VERSION ""

NS_ :

BS_:

BU_: ACM AMP BCM DIAG_TEST EMCM ESEM ETM HMSM IPC LBSS RBSS TBM TTM

BO_ 1884 BCM_IGNITION_ON_COUNTER: 2 BCM
 SG_ IgnitionOnCounter : 7|16@0+ (1,0) [0|65535] "-" ACM,AMP,EMCM,ESEM,ETM,HMSM,LBSS,RBSS,TBM,TTM

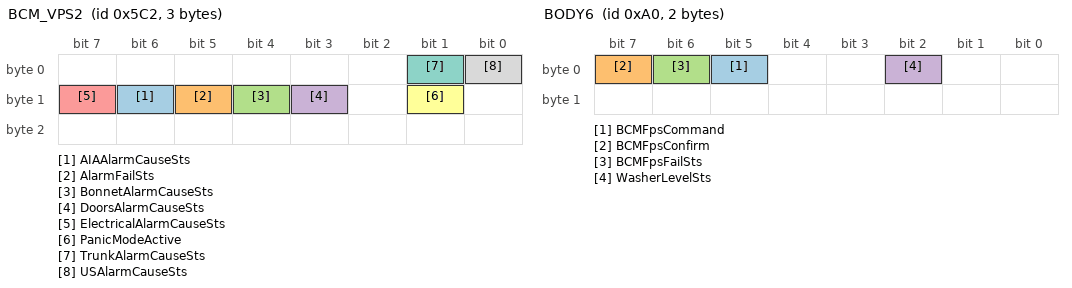
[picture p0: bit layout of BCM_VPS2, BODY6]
BO_ 1474 BCM_VPS2: 3 BCM
 SG_ AIAAlarmCauseSts : 14|1@0+ (1,0) [0|1] "-" IPC
 SG_ AlarmFailSts : 13|1@0+ (1,0) [0|1] "-" IPC
 SG_ BonnetAlarmCauseSts : 12|1@0+ (1,0) [0|1] "-" IPC
 SG_ DoorsAlarmCauseSts : 11|1@0+ (1,0) [0|1] "-" IPC
 SG_ ElectricalAlarmCauseSts : 15|1@0+ (1,0) [0|1] "-" IPC
 SG_ PanicModeActive : 9|1@0+ (1,0) [0|1] "-" ETM
 SG_ TrunkAlarmCauseSts : 1|1@0+ (1,0) [0|1] "-" IPC
 SG_ USAlarmCauseSts : 0|1@0+ (1,0) [0|1] "-" IPC

BO_ 160 BODY6: 2 BCM
 SG_ BCMFpsCommand : 5|1@0+ (1,0) [0|1] "-" ACM
 SG_ BCMFpsConfirm : 7|1@0+ (1,0) [0|1] "-" ACM
 SG_ BCMFpsFailSts : 6|1@0+ (1,0) [0|1] "-" ACM
 SG_ WasherLevelSts : 2|1@0+ (1,0) [0|1] "-" IPC

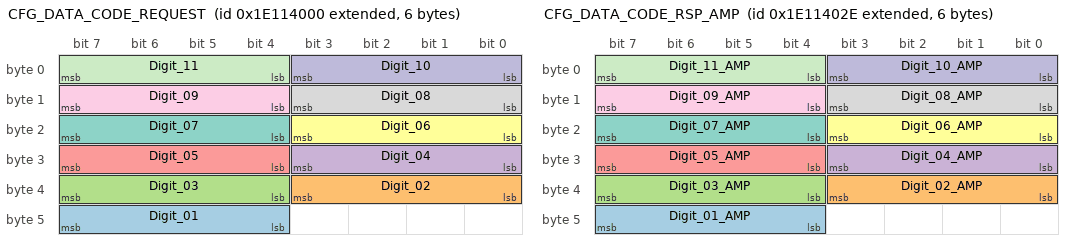
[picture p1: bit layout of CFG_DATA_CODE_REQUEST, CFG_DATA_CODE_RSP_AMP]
BO_ 2651930624 CFG_DATA_CODE_REQUEST: 6 BCM
 SG_ Digit_01 : 47|4@0+ (1,0) [0|15] "" ACM,AMP,EMCM,ESEM,ETM,HMSM,LBSS,RBSS,TBM,TTM
 SG_ Digit_02 : 35|4@0+ (1,0) [0|15] "" ACM,AMP,EMCM,ESEM,ETM,HMSM,LBSS,RBSS,TBM,TTM
 SG_ Digit_03 : 39|4@0+ (1,0) [0|15] "" ACM,AMP,EMCM,ESEM,ETM,HMSM,LBSS,RBSS,TBM,TTM
 SG_ Digit_04 : 27|4@0+ (1,0) [0|15] "" ACM,AMP,EMCM,ESEM,ETM,HMSM,LBSS,RBSS,TBM,TTM
 SG_ Digit_05 : 31|4@0+ (1,0) [0|15] "" ACM,AMP,EMCM,ESEM,ETM,HMSM,LBSS,RBSS,TBM,TTM
 SG_ Digit_06 : 19|4@0+ (1,0) [0|15] "" ACM,AMP,EMCM,ESEM,ETM,HMSM,LBSS,RBSS,TBM,TTM
 SG_ Digit_07 : 23|4@0+ (1,0) [0|15] "" ACM,AMP,EMCM,ESEM,ETM,HMSM,LBSS,RBSS,TBM,TTM
 SG_ Digit_08 : 11|4@0+ (1,0) [0|15] "" ACM,AMP,EMCM,ESEM,ETM,HMSM,LBSS,RBSS,TBM,TTM
 SG_ Digit_09 : 15|4@0+ (1,0) [0|15] "" ACM,AMP,EMCM,ESEM,ETM,HMSM,LBSS,RBSS,TBM,TTM
 SG_ Digit_10 : 3|4@0+ (1,0) [0|15] "" ACM,AMP,EMCM,ESEM,ETM,HMSM,LBSS,RBSS,TBM,TTM
 SG_ Digit_11 : 7|4@0+ (1,0) [0|15] "" ACM,AMP,EMCM,ESEM,ETM,HMSM,LBSS,RBSS,TBM,TTM

BO_ 2651930670 CFG_DATA_CODE_RSP_AMP: 6 AMP
 SG_ Digit_01_AMP : 47|4@0+ (1,0) [0|15] "-" BCM
 SG_ Digit_02_AMP : 35|4@0+ (1,0) [0|15] "-" BCM
 SG_ Digit_03_AMP : 39|4@0+ (1,0) [0|15] "-" BCM
 SG_ Digit_04_AMP : 27|4@0+ (1,0) [0|15] "-" BCM
 SG_ Digit_05_AMP : 31|4@0+ (1,0) [0|15] "-" BCM
 SG_ Digit_06_AMP : 19|4@0+ (1,0) [0|15] "-" BCM
 SG_ Digit_07_AMP : 23|4@0+ (1,0) [0|15] "-" BCM
 SG_ Digit_08_AMP : 11|4@0+ (1,0) [0|15] "-" BCM
 SG_ Digit_09_AMP : 15|4@0+ (1,0) [0|15] "-" BCM
 SG_ Digit_10_AMP : 3|4@0+ (1,0) [0|15] "-" BCM
 SG_ Digit_11_AMP : 7|4@0+ (1,0) [0|15] "-" BCM

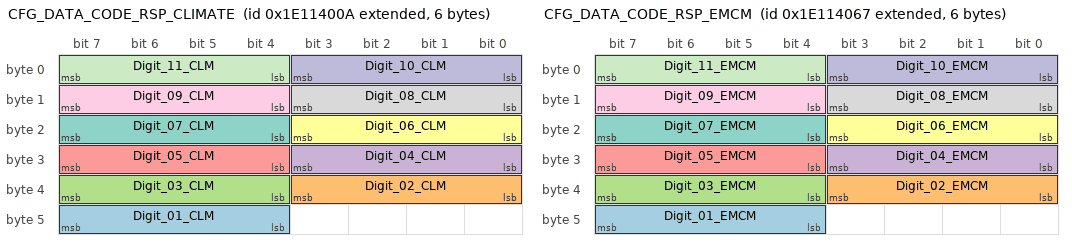
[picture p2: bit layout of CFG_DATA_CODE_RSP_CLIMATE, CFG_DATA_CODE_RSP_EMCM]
BO_ 2651930634 CFG_DATA_CODE_RSP_CLIMATE: 6 ACM
 SG_ Digit_01_CLM : 47|4@0+ (1,0) [0|15] "-" BCM
 SG_ Digit_02_CLM : 35|4@0+ (1,0) [0|15] "-" BCM
 SG_ Digit_03_CLM : 39|4@0+ (1,0) [0|15] "-" BCM
 SG_ Digit_04_CLM : 27|4@0+ (1,0) [0|15] "-" BCM
 SG_ Digit_05_CLM : 31|4@0+ (1,0) [0|15] "-" BCM
 SG_ Digit_06_CLM : 19|4@0+ (1,0) [0|15] "-" BCM
 SG_ Digit_07_CLM : 23|4@0+ (1,0) [0|15] "-" BCM
 SG_ Digit_08_CLM : 11|4@0+ (1,0) [0|15] "-" BCM
 SG_ Digit_09_CLM : 15|4@0+ (1,0) [0|15] "-" BCM
 SG_ Digit_10_CLM : 3|4@0+ (1,0) [0|15] "-" BCM
 SG_ Digit_11_CLM : 7|4@0+ (1,0) [0|15] "-" BCM

BO_ 2651930727 CFG_DATA_CODE_RSP_EMCM: 6 EMCM
 SG_ Digit_01_EMCM : 47|4@0+ (1,0) [0|15] "-" BCM
 SG_ Digit_02_EMCM : 35|4@0+ (1,0) [0|15] "-" BCM
 SG_ Digit_03_EMCM : 39|4@0+ (1,0) [0|15] "-" BCM
 SG_ Digit_04_EMCM : 27|4@0+ (1,0) [0|15] "-" BCM
 SG_ Digit_05_EMCM : 31|4@0+ (1,0) [0|15] "-" BCM
 SG_ Digit_06_EMCM : 19|4@0+ (1,0) [0|15] "-" BCM
 SG_ Digit_07_EMCM : 23|4@0+ (1,0) [0|15] "-" BCM
 SG_ Digit_08_EMCM : 11|4@0+ (1,0) [0|15] "-" BCM
 SG_ Digit_09_EMCM : 15|4@0+ (1,0) [0|15] "-" BCM
 SG_ Digit_10_EMCM : 3|4@0+ (1,0) [0|15] "-" BCM
 SG_ Digit_11_EMCM : 7|4@0+ (1,0) [0|15] "-" BCM

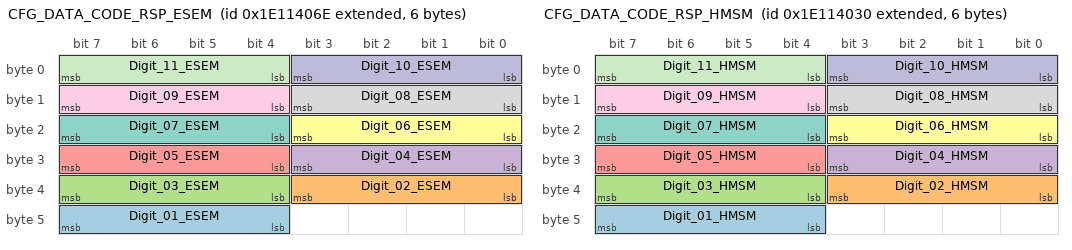
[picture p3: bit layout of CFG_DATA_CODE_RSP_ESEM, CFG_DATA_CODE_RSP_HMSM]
BO_ 2651930734 CFG_DATA_CODE_RSP_ESEM: 6 ESEM
 SG_ Digit_01_ESEM : 47|4@0+ (1,0) [0|15] "-" BCM
 SG_ Digit_02_ESEM : 35|4@0+ (1,0) [0|15] "-" BCM
 SG_ Digit_03_ESEM : 39|4@0+ (1,0) [0|15] "-" BCM
 SG_ Digit_04_ESEM : 27|4@0+ (1,0) [0|15] "-" BCM
 SG_ Digit_05_ESEM : 31|4@0+ (1,0) [0|15] "-" BCM
 SG_ Digit_06_ESEM : 19|4@0+ (1,0) [0|15] "-" BCM
 SG_ Digit_07_ESEM : 23|4@0+ (1,0) [0|15] "-" BCM
 SG_ Digit_08_ESEM : 11|4@0+ (1,0) [0|15] "-" BCM
 SG_ Digit_09_ESEM : 15|4@0+ (1,0) [0|15] "-" BCM
 SG_ Digit_10_ESEM : 3|4@0+ (1,0) [0|15] "-" BCM
 SG_ Digit_11_ESEM : 7|4@0+ (1,0) [0|15] "-" BCM

BO_ 2651930672 CFG_DATA_CODE_RSP_HMSM: 6 HMSM
 SG_ Digit_01_HMSM : 47|4@0+ (1,0) [0|15] "-" BCM
 SG_ Digit_02_HMSM : 35|4@0+ (1,0) [0|15] "-" BCM
 SG_ Digit_03_HMSM : 39|4@0+ (1,0) [0|15] "-" BCM
 SG_ Digit_04_HMSM : 27|4@0+ (1,0) [0|15] "-" BCM
 SG_ Digit_05_HMSM : 31|4@0+ (1,0) [0|15] "-" BCM
 SG_ Digit_06_HMSM : 19|4@0+ (1,0) [0|15] "-" BCM
 SG_ Digit_07_HMSM : 23|4@0+ (1,0) [0|15] "-" BCM
 SG_ Digit_08_HMSM : 11|4@0+ (1,0) [0|15] "-" BCM
 SG_ Digit_09_HMSM : 15|4@0+ (1,0) [0|15] "-" BCM
 SG_ Digit_10_HMSM : 3|4@0+ (1,0) [0|15] "-" BCM
 SG_ Digit_11_HMSM : 7|4@0+ (1,0) [0|15] "-" BCM

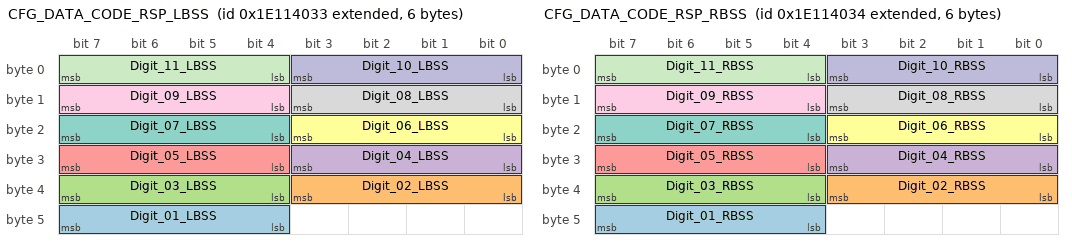
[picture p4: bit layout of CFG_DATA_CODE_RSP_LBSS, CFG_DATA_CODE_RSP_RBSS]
BO_ 2651930675 CFG_DATA_CODE_RSP_LBSS: 6 LBSS
 SG_ Digit_01_LBSS : 47|4@0+ (1,0) [0|15] "-" BCM
 SG_ Digit_02_LBSS : 35|4@0+ (1,0) [0|15] "-" BCM
 SG_ Digit_03_LBSS : 39|4@0+ (1,0) [0|15] "-" BCM
 SG_ Digit_04_LBSS : 27|4@0+ (1,0) [0|15] "-" BCM
 SG_ Digit_05_LBSS : 31|4@0+ (1,0) [0|15] "-" BCM
 SG_ Digit_06_LBSS : 19|4@0+ (1,0) [0|15] "-" BCM
 SG_ Digit_07_LBSS : 23|4@0+ (1,0) [0|15] "-" BCM
 SG_ Digit_08_LBSS : 11|4@0+ (1,0) [0|15] "-" BCM
 SG_ Digit_09_LBSS : 15|4@0+ (1,0) [0|15] "-" BCM
 SG_ Digit_10_LBSS : 3|4@0+ (1,0) [0|15] "-" BCM
 SG_ Digit_11_LBSS : 7|4@0+ (1,0) [0|15] "-" BCM

BO_ 2651930676 CFG_DATA_CODE_RSP_RBSS: 6 RBSS
 SG_ Digit_01_RBSS : 47|4@0+ (1,0) [0|15] "-" BCM
 SG_ Digit_02_RBSS : 35|4@0+ (1,0) [0|15] "-" BCM
 SG_ Digit_03_RBSS : 39|4@0+ (1,0) [0|15] "-" BCM
 SG_ Digit_04_RBSS : 27|4@0+ (1,0) [0|15] "-" BCM
 SG_ Digit_05_RBSS : 31|4@0+ (1,0) [0|15] "-" BCM
 SG_ Digit_06_RBSS : 19|4@0+ (1,0) [0|15] "-" BCM
 SG_ Digit_07_RBSS : 23|4@0+ (1,0) [0|15] "-" BCM
 SG_ Digit_08_RBSS : 11|4@0+ (1,0) [0|15] "-" BCM
 SG_ Digit_09_RBSS : 15|4@0+ (1,0) [0|15] "-" BCM
 SG_ Digit_10_RBSS : 3|4@0+ (1,0) [0|15] "-" BCM
 SG_ Digit_11_RBSS : 7|4@0+ (1,0) [0|15] "-" BCM

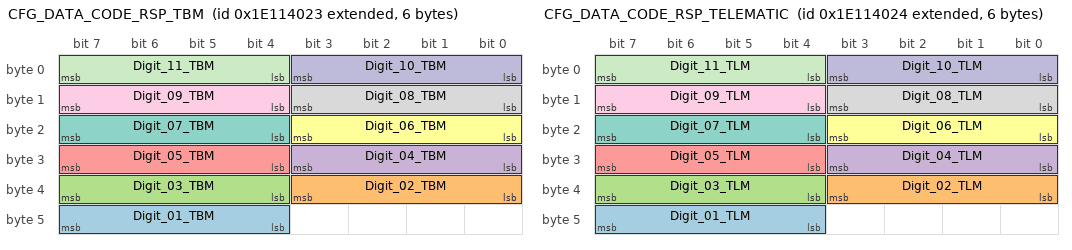
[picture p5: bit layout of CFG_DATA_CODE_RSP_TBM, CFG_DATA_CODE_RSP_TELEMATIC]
BO_ 2651930659 CFG_DATA_CODE_RSP_TBM: 6 TBM
 SG_ Digit_01_TBM : 47|4@0+ (1,0) [0|15] "-" BCM
 SG_ Digit_02_TBM : 35|4@0+ (1,0) [0|15] "-" BCM
 SG_ Digit_03_TBM : 39|4@0+ (1,0) [0|15] "-" BCM
 SG_ Digit_04_TBM : 27|4@0+ (1,0) [0|15] "-" BCM
 SG_ Digit_05_TBM : 31|4@0+ (1,0) [0|15] "-" BCM
 SG_ Digit_06_TBM : 19|4@0+ (1,0) [0|15] "-" BCM
 SG_ Digit_07_TBM : 23|4@0+ (1,0) [0|15] "-" BCM
 SG_ Digit_08_TBM : 11|4@0+ (1,0) [0|15] "-" BCM
 SG_ Digit_09_TBM : 15|4@0+ (1,0) [0|15] "-" BCM
 SG_ Digit_10_TBM : 3|4@0+ (1,0) [0|15] "-" BCM
 SG_ Digit_11_TBM : 7|4@0+ (1,0) [0|15] "-" BCM

BO_ 2651930660 CFG_DATA_CODE_RSP_TELEMATIC: 6 ETM
 SG_ Digit_01_TLM : 47|4@0+ (1,0) [0|15] "-" BCM
 SG_ Digit_02_TLM : 35|4@0+ (1,0) [0|15] "-" BCM
 SG_ Digit_03_TLM : 39|4@0+ (1,0) [0|15] "-" BCM
 SG_ Digit_04_TLM : 27|4@0+ (1,0) [0|15] "-" BCM
 SG_ Digit_05_TLM : 31|4@0+ (1,0) [0|15] "-" BCM
 SG_ Digit_06_TLM : 19|4@0+ (1,0) [0|15] "-" BCM
 SG_ Digit_07_TLM : 23|4@0+ (1,0) [0|15] "-" BCM
 SG_ Digit_08_TLM : 11|4@0+ (1,0) [0|15] "-" BCM
 SG_ Digit_09_TLM : 15|4@0+ (1,0) [0|15] "-" BCM
 SG_ Digit_10_TLM : 3|4@0+ (1,0) [0|15] "-" BCM
 SG_ Digit_11_TLM : 7|4@0+ (1,0) [0|15] "-" BCM

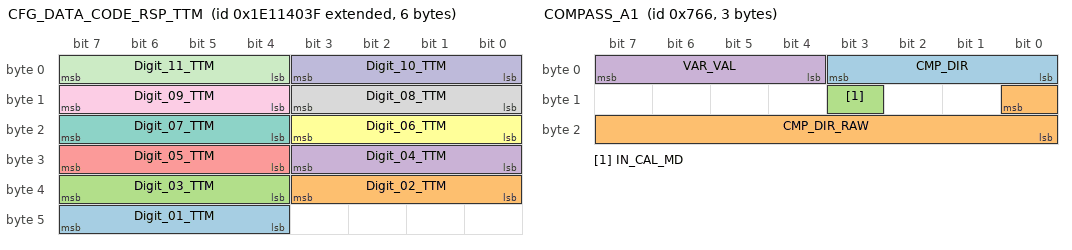
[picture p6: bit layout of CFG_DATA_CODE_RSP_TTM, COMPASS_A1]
BO_ 2651930687 CFG_DATA_CODE_RSP_TTM: 6 TTM
 SG_ Digit_01_TTM : 47|4@0+ (1,0) [0|15] "-" BCM
 SG_ Digit_02_TTM : 35|4@0+ (1,0) [0|15] "-" BCM
 SG_ Digit_03_TTM : 39|4@0+ (1,0) [0|15] "-" BCM
 SG_ Digit_04_TTM : 27|4@0+ (1,0) [0|15] "-" BCM
 SG_ Digit_05_TTM : 31|4@0+ (1,0) [0|15] "-" BCM
 SG_ Digit_06_TTM : 19|4@0+ (1,0) [0|15] "-" BCM
 SG_ Digit_07_TTM : 23|4@0+ (1,0) [0|15] "-" BCM
 SG_ Digit_08_TTM : 11|4@0+ (1,0) [0|15] "-" BCM
 SG_ Digit_09_TTM : 15|4@0+ (1,0) [0|15] "-" BCM
 SG_ Digit_10_TTM : 3|4@0+ (1,0) [0|15] "-" BCM
 SG_ Digit_11_TTM : 7|4@0+ (1,0) [0|15] "-" BCM

BO_ 134 CLIMATE_REQ: 2 ACM
 SG_ FPS_Status_Request : 7|1@0+ (1,0) [0|1] "-" BCM

BO_ 1894 COMPASS_A1: 3 IPC
 SG_ CMP_DIR : 3|4@0+ (1,0) [0|15] "" ETM
 SG_ CMP_DIR_RAW : 8|9@0+ (1,0) [0|0] "" Vector__XXX
 SG_ IN_CAL_MD : 11|1@0+ (1,0) [0|0] "" ETM
 SG_ VAR_VAL : 7|4@0+ (1,0) [0|0] "" ETM

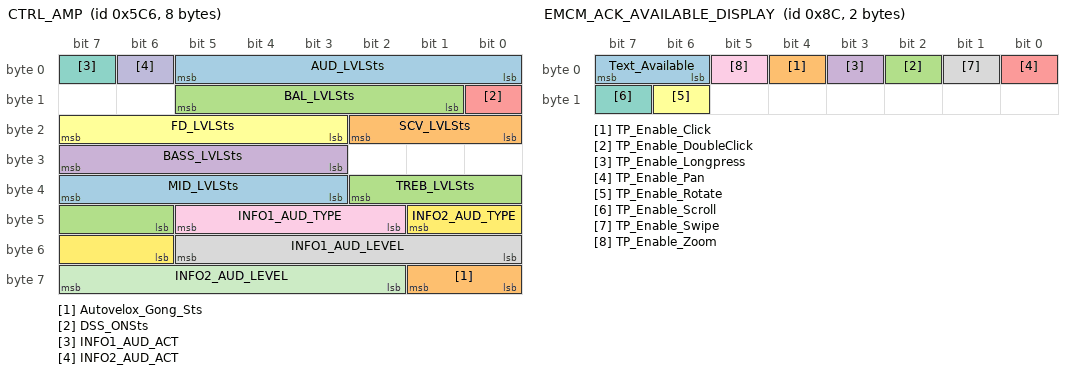
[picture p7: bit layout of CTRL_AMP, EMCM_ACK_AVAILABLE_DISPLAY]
BO_ 1478 CTRL_AMP: 8 ETM
 SG_ AUD_LVLSts : 5|6@0+ (1,0) [0|63] "" AMP
 SG_ Autovelox_Gong_Sts : 57|2@0+ (1,0) [0|3] "" AMP
 SG_ BAL_LVLSts : 13|5@0+ (1,0) [0|31] "" AMP
 SG_ BASS_LVLSts : 31|5@0+ (1,0) [0|31] "" AMP
 SG_ DSS_ONSts : 8|1@0+ (1,0) [0|1] "" AMP
 SG_ FD_LVLSts : 23|5@0+ (1,0) [0|31] "" AMP
 SG_ INFO1_AUD_ACT : 7|1@0+ (1,0) [0|1] "" AMP
 SG_ INFO1_AUD_LEVEL : 53|6@0+ (1,0) [0|63] "" AMP
 SG_ INFO1_AUD_TYPE : 45|4@0+ (1,0) [0|15] "" AMP
 SG_ INFO2_AUD_ACT : 6|1@0+ (1,0) [0|1] "" AMP
 SG_ INFO2_AUD_LEVEL : 63|6@0+ (1,0) [0|63] "" AMP
 SG_ INFO2_AUD_TYPE : 41|4@0+ (1,0) [0|15] "" AMP
 SG_ MID_LVLSts : 39|5@0+ (1,0) [0|31] "" AMP
 SG_ SCV_LVLSts : 18|3@0+ (1,0) [0|6] "" AMP
 SG_ TREB_LVLSts : 34|5@0+ (1,0) [0|31] "" AMP

BO_ 2564554481 DIAGNOSTIC_REQ_FUNC_BH_C2: 8 BCM
 SG_ N_PDU : 7|64@0+ (1,0) [0|0] "" ACM,AMP,BCM,EMCM,ESEM,ETM,HMSM,LBSS,RBSS,TBM,TTM

BO_ 2564457457 DIAGNOSTIC_REQUEST_AMP: 8 BCM
 SG_ N_PDU : 7|64@0+ (1,0) [0|0] "" AMP

BO_ 2564462833 DIAGNOSTIC_REQUEST_CLIMATE: 8 BCM
 SG_ N_PDU : 7|64@0+ (1,0) [0|0] "" ACM

BO_ 2564459249 DIAGNOSTIC_REQUEST_EMCM: 8 BCM
 SG_ N_PDU : 7|64@0+ (1,0) [0|0] "" EMCM

BO_ 2564459505 DIAGNOSTIC_REQUEST_ESEM: 8 BCM
 SG_ N_PDU : 7|64@0+ (1,0) [0|0] "" ESEM

BO_ 2564473585 DIAGNOSTIC_REQUEST_HMSM: 8 BCM
 SG_ N_PDU : 7|64@0+ (1,0) [0|0] "" HMSM

BO_ 2564449009 DIAGNOSTIC_REQUEST_LBSS: 8 BCM
 SG_ N_PDU : 7|64@0+ (1,0) [0|0] "" LBSS

BO_ 2564449777 DIAGNOSTIC_REQUEST_RBSS: 8 BCM
 SG_ N_PDU : 7|64@0+ (1,0) [0|0] "" RBSS

BO_ 2564474609 DIAGNOSTIC_REQUEST_TBM: 8 BCM
 SG_ N_PDU : 7|64@0+ (1,0) [0|0] "-" TBM

BO_ 2564458481 DIAGNOSTIC_REQUEST_TELEMATIC: 8 BCM
 SG_ N_PDU : 7|64@0+ (1,0) [0|0] "" EMCM,ESEM,ETM

BO_ 2564442865 DIAGNOSTIC_REQUEST_TTM: 8 BCM
 SG_ N_PDU : 7|64@0+ (1,0) [0|0] "" TTM

BO_ 2564485507 DIAGNOSTIC_RESPONSE_AMP: 8 AMP
 SG_ N_PDU : 7|64@0+ (1,0) [0|0] "-" BCM,DIAG_TEST

BO_ 2564485528 DIAGNOSTIC_RESPONSE_CLIMATE: 8 ACM
 SG_ N_PDU : 7|64@0+ (1,0) [0|0] "" BCM,DIAG_TEST

BO_ 2564485514 DIAGNOSTIC_RESPONSE_EMCM: 8 EMCM
 SG_ N_PDU : 7|64@0+ (1,0) [0|0] "-" DIAG_TEST

BO_ 2564485515 DIAGNOSTIC_RESPONSE_ESEM: 8 ESEM
 SG_ N_PDU : 7|64@0+ (1,0) [0|0] "" BCM,DIAG_TEST

BO_ 2564485570 DIAGNOSTIC_RESPONSE_HMSM: 8 HMSM
 SG_ N_PDU : 7|64@0+ (1,0) [0|0] "-" BCM,DIAG_TEST

BO_ 2564485474 DIAGNOSTIC_RESPONSE_LBSS: 8 LBSS
 SG_ N_PDU : 7|64@0+ (1,0) [0|0] "-" BCM,DIAG_TEST

BO_ 2564485477 DIAGNOSTIC_RESPONSE_RBSS: 8 RBSS
 SG_ N_PDU : 7|64@0+ (1,0) [0|0] "-" BCM,DIAG_TEST

BO_ 2564485574 DIAGNOSTIC_RESPONSE_TBM: 8 TBM
 SG_ N_PDU : 7|64@0+ (1,0) [0|0] "-" BCM,DIAG_TEST

BO_ 2564485511 DIAGNOSTIC_RESPONSE_TELEMATIC: 8 ETM
 SG_ N_PDU : 7|64@0+ (1,0) [0|0] "" BCM,DIAG_TEST

BO_ 2564485450 DIAGNOSTIC_RESPONSE_TTM: 8 TTM
 SG_ N_PDU : 7|64@0+ (1,0) [0|0] "-" BCM,DIAG_TEST

BO_ 140 EMCM_ACK_AVAILABLE_DISPLAY: 2 EMCM
 SG_ Text_Available : 7|2@0+ (1,0) [0|3] "-" ETM
 SG_ TP_Enable_Click : 4|1@0+ (1,0) [0|1] "-" ETM
 SG_ TP_Enable_DoubleClick : 2|1@0+ (1,0) [0|1] "-" ETM
 SG_ TP_Enable_Longpress : 3|1@0+ (1,0) [0|1] "-" ETM
 SG_ TP_Enable_Pan : 0|1@0+ (1,0) [0|1] "-" ETM
 SG_ TP_Enable_Rotate : 14|1@0+ (1,0) [0|1] "-" ETM
 SG_ TP_Enable_Scroll : 15|1@0+ (1,0) [0|1] "-" ETM
 SG_ TP_Enable_Swipe : 1|1@0+ (1,0) [0|1] "-" ETM
 SG_ TP_Enable_Zoom : 5|1@0+ (1,0) [0|1] "-" ETM

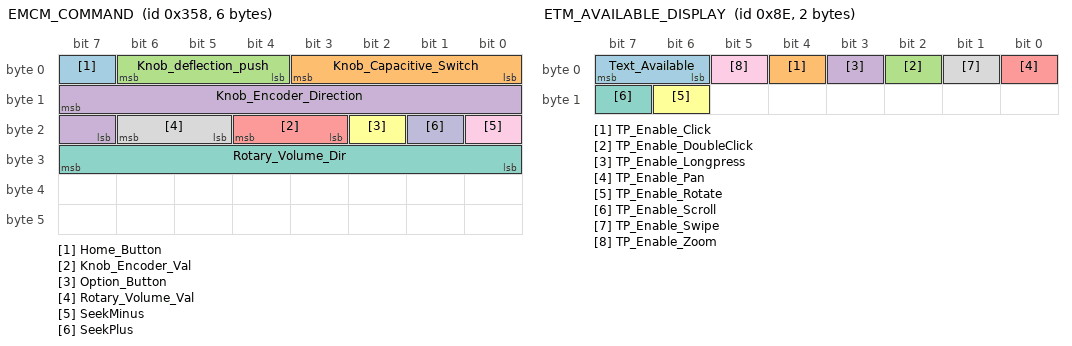
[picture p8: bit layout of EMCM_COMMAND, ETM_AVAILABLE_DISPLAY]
BO_ 856 EMCM_COMMAND: 6 EMCM
 SG_ Home_Button : 7|1@0+ (1,0) [0|1] "-" ETM
 SG_ Knob_Capacitive_Switch : 3|4@0+ (1,0) [0|15] "-" ETM
 SG_ Knob_deflection_push : 6|3@0+ (1,0) [0|3] "-" ETM
 SG_ Knob_Encoder_Direction : 15|9@0+ (1,0) [0|511] "-" ETM
 SG_ Knob_Encoder_Val : 20|2@0+ (1,0) [0|3] "-" ETM
 SG_ Option_Button : 18|1@0+ (1,0) [0|1] "-" ETM
 SG_ Rotary_Volume_Dir : 31|8@0+ (1,0) [0|255] "-" ETM
 SG_ Rotary_Volume_Val : 22|2@0+ (1,0) [0|3] "-" ETM
 SG_ SeekMinus : 16|1@0+ (1,0) [0|1] "-" ETM
 SG_ SeekPlus : 17|1@0+ (1,0) [0|1] "-" ETM

BO_ 142 ETM_AVAILABLE_DISPLAY: 2 ETM
 SG_ Text_Available : 7|2@0+ (1,0) [0|3] "-" EMCM
 SG_ TP_Enable_Click : 4|1@0+ (1,0) [0|1] "-" EMCM
 SG_ TP_Enable_DoubleClick : 2|1@0+ (1,0) [0|1] "-" EMCM
 SG_ TP_Enable_Longpress : 3|1@0+ (1,0) [0|1] "-" EMCM
 SG_ TP_Enable_Pan : 0|1@0+ (1,0) [0|1] "-" EMCM
 SG_ TP_Enable_Rotate : 14|1@0+ (1,0) [0|1] "-" EMCM
 SG_ TP_Enable_Scroll : 15|1@0+ (1,0) [0|1] "-" EMCM
 SG_ TP_Enable_Swipe : 1|1@0+ (1,0) [0|1] "-" EMCM
 SG_ TP_Enable_Zoom : 5|1@0+ (1,0) [0|1] "-" EMCM

BO_ 852 EXTERNAL_LIGHTS: 4 BCM
 SG_ AHBFeature : 19|1@0+ (1,0) [0|1] "-" IPC
 SG_ ALBFeature : 30|1@0+ (1,0) [0|1] "-" IPC
 SG_ DRLFault : 6|1@0+ (1,0) [0|1] "-" IPC
 SG_ FHeatedWindowSts : 5|1@0+ (1,0) [0|1] "-" ACM
 SG_ FrontFogLightSts : 4|1@0+ (1,0) [0|1] "-" IPC
 SG_ HeatedMirrorSts : 3|1@0+ (1,0) [0|1] "-" Vector__XXX
 SG_ HighBeamSts : 2|1@0+ (1,0) [0|1] "-" IPC
 SG_ L_TurnLightActivationSts : 17|1@0+ (1,0) [0|1] "-" Vector__XXX
 SG_ LHParkingLightSts : 1|1@0+ (1,0) [0|1] "-" IPC,TTM
 SG_ LHTurnLightFault : 0|1@0+ (1,0) [0|1] "-" IPC
 SG_ LHTurnSignalSts : 15|1@0+ (1,0) [0|1] "-" IPC,TTM
 SG_ LowBeamSts : 14|1@0+ (1,0) [0|1] "-" BCM,IPC
 SG_ ParkingLightFault : 13|1@0+ (1,0) [0|1] "-" IPC
 SG_ PlateLightFault : 12|1@0+ (1,0) [0|1] "-" IPC
 SG_ R_TurnLightActivationSts : 16|1@0+ (1,0) [0|1] "-" Vector__XXX
 SG_ RearFogLightFault : 11|1@0+ (1,0) [0|1] "-" IPC
 SG_ RearFogLightSts : 10|1@0+ (1,0) [0|1] "-" IPC,TTM
 SG_ ReverseGearLightFault : 9|1@0+ (1,0) [0|1] "-" IPC
 SG_ RHeatedWindowSts : 8|1@0+ (1,0) [0|1] "-" ACM
 SG_ RHParkingLightSts : 23|1@0+ (1,0) [0|1] "-" IPC,TTM
 SG_ RHTurnLightFault : 22|1@0+ (1,0) [0|1] "-" IPC
 SG_ RHTurnSignalSts : 21|1@0+ (1,0) [0|1] "-" IPC,TTM
 SG_ StopLightFault : 20|1@0+ (1,0) [0|1] "-" IPC
 SG_ StopLightSts : 18|1@0+ (1,0) [0|1] "-" TTM

BO_ 2147485498 GPS_POS1: 8 TBM
 SG_ GPS_POS1_Lat : 39|32@0+ (0.3017485143,-324000000) [-324000000|324000000] "mass" Vector__XXX
 SG_ GPS_POS1_Long : 7|32@0+ (0.3017485143,-324000000) [-324000000|324000000] "mass" Vector__XXX

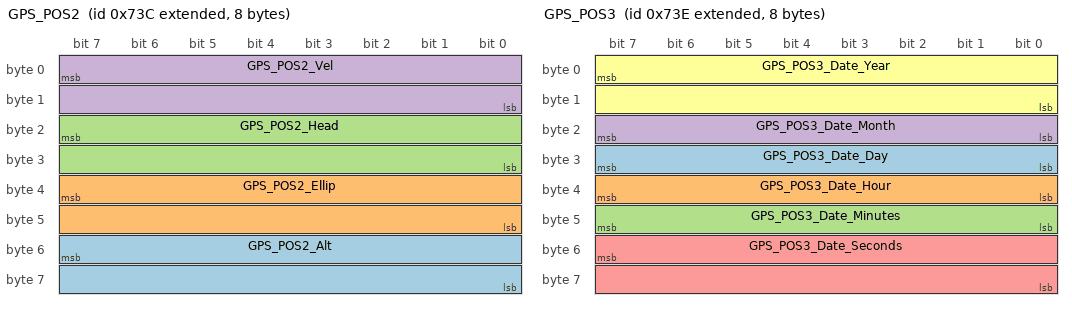
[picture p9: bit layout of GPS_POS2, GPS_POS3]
BO_ 2147485500 GPS_POS2: 8 TBM
 SG_ GPS_POS2_Alt : 55|16@0+ (0.289926,-1000) [-1000|18000] "m" Vector__XXX
 SG_ GPS_POS2_Ellip : 39|16@0+ (0.289926,-1000) [-1000|18000] "m" Vector__XXX
 SG_ GPS_POS2_Head : 23|16@0+ (0.1,0) [0|359.9] "°" Vector__XXX
 SG_ GPS_POS2_Vel : 7|16@0+ (1,0) [0|65534] "cm/sec" Vector__XXX

BO_ 2147485502 GPS_POS3: 8 TBM
 SG_ GPS_POS3_Date_Day : 31|8@0+ (31,1) [1|31] "days" Vector__XXX
 SG_ GPS_POS3_Date_Hour : 39|8@0+ (1,0) [0|23] "hours" Vector__XXX
 SG_ GPS_POS3_Date_Minutes : 47|8@0+ (59,0) [0|59] "minutes" Vector__XXX
 SG_ GPS_POS3_Date_Month : 23|8@0+ (1,0) [1|12] "months" Vector__XXX
 SG_ GPS_POS3_Date_Seconds : 55|16@0+ (0.01,0) [0|59.99] "seconds" Vector__XXX
 SG_ GPS_POS3_Date_Year : 7|16@0+ (1,0) [0|65534] "years" Vector__XXX

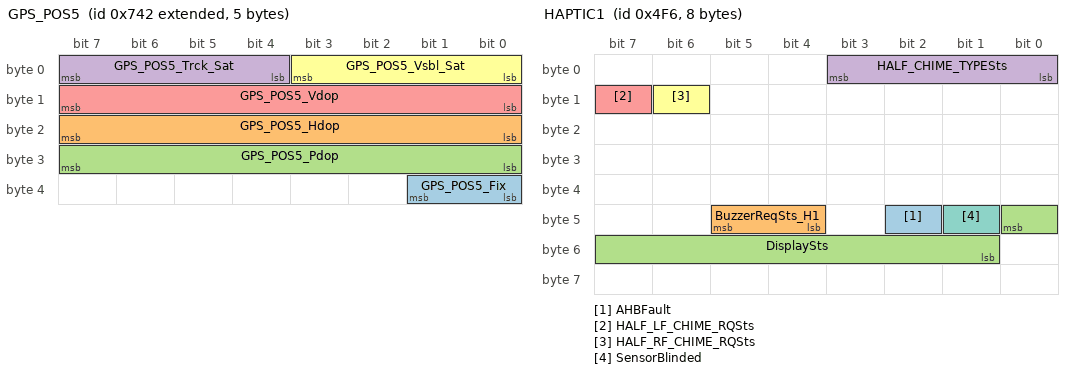
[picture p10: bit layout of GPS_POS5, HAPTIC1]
BO_ 2147485506 GPS_POS5: 5 TBM
 SG_ GPS_POS5_Fix : 33|2@0+ (1,0) [0|0] "-" Vector__XXX
 SG_ GPS_POS5_Hdop : 23|8@0+ (0.1,0) [1|8] "" Vector__XXX
 SG_ GPS_POS5_Pdop : 31|8@0+ (0.1,0) [1|8] "" Vector__XXX
 SG_ GPS_POS5_Trck_Sat : 7|4@0+ (1,0) [0|12] "" Vector__XXX
 SG_ GPS_POS5_Vdop : 15|8@0+ (0.1,0) [1|8] "" Vector__XXX
 SG_ GPS_POS5_Vsbl_Sat : 3|4@0+ (1,0) [0|12] "" Vector__XXX

BO_ 1270 HAPTIC1: 8 BCM
 SG_ AHBFault : 42|1@0+ (1,0) [0|1] "" IPC
 SG_ BuzzerReqSts_H1 : 45|2@0+ (1,0) [0|3] "" IPC
 SG_ DisplaySts : 40|8@0+ (1,0) [0|255] "-" IPC
 SG_ HALF_CHIME_TYPESts : 3|4@0+ (1,0) [0|15] "-" AMP,ETM
 SG_ HALF_LF_CHIME_RQSts : 15|1@0+ (1,0) [0|1] "-" AMP,ETM
 SG_ HALF_RF_CHIME_RQSts : 14|1@0+ (1,0) [0|1] "-" AMP,ETM
 SG_ SensorBlinded : 41|1@0+ (1,0) [0|1] "" IPC

BO_ 986 IPC_ACK: 1 IPC
 SG_ DisplayInfoReceptionSts : 7|1@0+ (1,0) [0|1] "-" ETM

BO_ 1468 IPC_VEHICLE_SETUP: 8 IPC
 SG_ AmbientLightingLevel : 48|4@0+ (1,0) [0|15] "" BCM,ETM
 SG_ AudioRepetition : 46|1@0+ (1,0) [0|1] "" ETM
 SG_ AutoHighBeamEnable : 21|1@0+ (1,0) [0|1] "-" BCM,ETM
 SG_ AutomaticResetTripB : 37|2@0+ (1,0) [0|3] "" ETM
 SG_ AutoParkBrake : 47|1@0+ (1,0) [0|1] "" ETM
 SG_ AutoRelock : 51|1@0+ (1,0) [0|1] "" ETM
 SG_ BSDEnable : 30|2@0+ (1,0) [0|3] "" ETM,LBSS,RBSS
 SG_ ConsumptionUnit : 15|3@0+ (1,0) [0|7] "-" ETM
 SG_ CorneringEnable : 18|1@0+ (1,0) [0|1] "-" BCM,ETM
 SG_ DistanceUnit : 10|1@0+ (1,0) [0|1] "-" ETM
 SG_ DRLEnable : 12|1@0+ (1,0) [0|1] "-" BCM,ETM
 SG_ ExternalLightSensorLevel : 9|2@0+ (1,0) [0|3] "-" BCM,ETM
 SG_ GreetingLightsEnable : 11|1@0+ (1,0) [0|1] "-" BCM,ETM
 SG_ HourMode : 23|1@0+ (1,0) [0|1] "-" ETM
 SG_ LanguageSelection : 7|8@0+ (1,0) [0|255] "-" ETM,TBM
 SG_ NavRepetition : 50|1@0+ (1,0) [0|1] "" ETM
 SG_ PamAlertMode : 43|2@0+ (1,0) [0|3] "-" AMP,ETM
 SG_ PamChimeVolumeFront : 45|2@0+ (1,0) [0|3] "" AMP,ETM
 SG_ PamChimeVolumeRear : 41|2@0+ (1,0) [0|3] "" AMP,ETM
 SG_ PassiveEntry : 28|1@0+ (1,0) [0|1] "" BCM,ETM
 SG_ PhoneRepetition : 49|1@0+ (1,0) [0|1] "" ETM
 SG_ RemoteDoorUnlock : 32|1@0+ (1,0) [0|1] "" BCM,ETM
 SG_ Sdw : 55|2@0+ (1,0) [0|3] "" Vector__XXX
 SG_ SdwChimeVolume : 53|2@0+ (1,0) [0|3] "" Vector__XXX
 SG_ SoundHornLock : 35|2@0+ (1,0) [0|3] "" BCM,ETM
 SG_ SoundHornRemoteStart : 33|1@0+ (1,0) [0|1] "" BCM,ETM
 SG_ SpeedLockDoorEnable : 20|1@0+ (1,0) [0|1] "-" BCM,ETM
 SG_ TelematicSetupACK : 16|2@0+ (1,0) [0|3] "-" ETM
 SG_ TemperatureUnit : 19|1@0+ (1,0) [0|1] "-" ACM,ETM
 SG_ TripBEnable : 17|1@0+ (1,0) [0|1] "" ETM

BO_ 1486 IPC_VEHICLE_SETUP2: 8 IPC
 SG_ AutoUnlockDoorExit : 5|1@0+ (1,0) [0|1] "-" BCM,ETM
 SG_ BrakeService : 38|1@0+ (1,0) [0|1] "-" ETM
 SG_ BuzzerVolume : 42|2@0+ (1,0) [0|3] "-" ETM
 SG_ CalibrationSetup : 32|1@0+ (1,0) [0|1] "-" ETM
 SG_ EPB_Maintenance_Fdbk : 21|5@0+ (1,0) [0|31] "-" ETM
 SG_ EPB_MaintenanceMode : 7|1@0+ (1,0) [0|1] "-" ETM
 SG_ FlashLightWLock : 6|1@0+ (1,0) [0|1] "-" BCM,ETM
 SG_ FrontPassengerAirBag : 40|2@0+ (1,0) [0|3] "-" ETM
 SG_ FSFCWPlusActivationMode : 23|2@0+ (1,0) [0|3] "-" ETM
 SG_ FSFCWPlusSetting : 10|3@0+ (1,0) [0|7] "-" ETM
 SG_ HeadlightsOffDelay : 4|2@0+ (1,0) [0|3] "-" BCM,ETM
 SG_ HHDisabling : 37|1@0+ (1,0) [0|1] "-" ETM
 SG_ LDW_Sensibility : 0|2@0+ (1,0) [0|3] "-" BCM,ETM
 SG_ SeltBeltReminder : 39|1@0+ (1,0) [0|1] "-" Vector__XXX
 SG_ SpeedLimitSet : 16|8@0+ (1,0) [0|255] "km/h" ETM
 SG_ SpeedLimitSts : 24|1@0+ (1,0) [0|1] "-" ETM
 SG_ TyrePressureUnit : 2|2@0+ (1,0) [0|3] "-" ETM
 SG_ Units : 12|2@0+ (1,0) [0|3] "-" ETM
 SG_ VarianceSet : 46|4@0+ (1,0) [0|15] "-" ETM

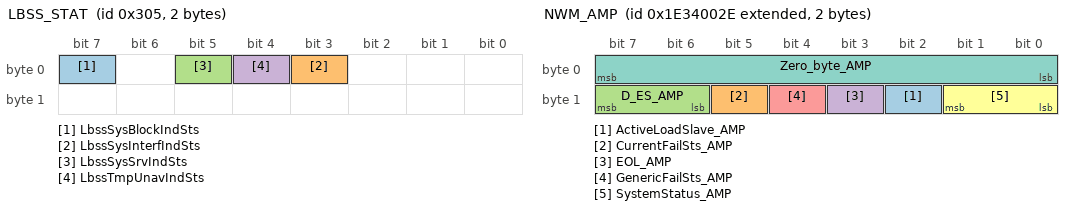
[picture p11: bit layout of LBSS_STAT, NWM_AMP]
BO_ 773 LBSS_STAT: 2 LBSS
 SG_ LbssSysBlockIndSts : 7|1@0+ (1,0) [0|1] "" RBSS
 SG_ LbssSysInterfIndSts : 3|1@0+ (1,0) [0|1] "" RBSS
 SG_ LbssSysSrvIndSts : 5|1@0+ (1,0) [0|1] "" RBSS
 SG_ LbssTmpUnavIndSts : 4|1@0+ (1,0) [0|1] "" RBSS

BO_ 2654208046 NWM_AMP: 2 AMP
 SG_ ActiveLoadSlave_AMP : 10|1@0+ (1,0) [0|1] "-" BCM
 SG_ CurrentFailSts_AMP : 13|1@0+ (1,0) [0|1] "-" BCM
 SG_ D_ES_AMP : 15|2@0+ (1,0) [0|3] "-" Vector__XXX
 SG_ EOL_AMP : 11|1@0+ (1,0) [0|1] "-" BCM
 SG_ GenericFailSts_AMP : 12|1@0+ (1,0) [0|1] "-" BCM
 SG_ SystemStatus_AMP : 9|2@0+ (1,0) [0|3] "-" BCM
 SG_ Zero_byte_AMP : 7|8@0+ (1,0) [0|0] "-" BCM

BO_ 2654208000 NWM_BCM: 6 BCM
 SG_ ActiveLoadMaster : 10|1@0+ (1,0) [0|1] "-" ACM,AMP,EMCM,ESEM,ETM,HMSM,IPC,LBSS,RBSS,TBM,TTM
 SG_ D_ES_BCM : 15|2@0+ (1,0) [0|3] "-" ACM,AMP,EMCM,ESEM,ETM,HMSM,IPC,LBSS,RBSS,TBM,TTM
 SG_ EOL_BCM : 11|1@0+ (1,0) [0|1] "-" ACM,AMP,EMCM,ESEM,ETM,HMSM,IPC,LBSS,RBSS,TBM,TTM
 SG_ GenericFailSts_BCM : 12|1@0+ (1,0) [0|1] "-" ACM,AMP,EMCM,ESEM,ETM,HMSM,IPC,LBSS,RBSS,TBM,TTM
 SG_ Node0 : 40|1@0+ (1,0) [0|1] "-" ACM,AMP,EMCM,ESEM,ETM,HMSM,IPC,LBSS,RBSS,TBM,TTM
 SG_ Node1 : 41|1@0+ (1,0) [0|1] "-" ACM,AMP,EMCM,ESEM,ETM,HMSM,IPC,LBSS,RBSS,TBM,TTM
 SG_ Node10 : 34|1@0+ (1,0) [0|1] "-" ACM,AMP,EMCM,ESEM,ETM,HMSM,IPC,LBSS,RBSS,TBM,TTM
 SG_ Node11 : 35|1@0+ (1,0) [0|1] "-" ACM,AMP,EMCM,ESEM,ETM,HMSM,IPC,LBSS,RBSS,TBM,TTM
 SG_ Node12 : 36|1@0+ (1,0) [0|1] "-" ACM,AMP,EMCM,ESEM,ETM,HMSM,IPC,LBSS,RBSS,TBM,TTM
 SG_ Node13 : 37|1@0+ (1,0) [0|1] "-" ACM,AMP,EMCM,ESEM,ETM,HMSM,IPC,LBSS,RBSS,TBM,TTM
 SG_ Node14 : 38|1@0+ (1,0) [0|1] "-" ACM,AMP,EMCM,ESEM,ETM,HMSM,IPC,LBSS,RBSS,TBM,TTM
 SG_ Node15 : 39|1@0+ (1,0) [0|1] "-" ACM,AMP,EMCM,ESEM,ETM,HMSM,IPC,LBSS,RBSS,TBM,TTM
 SG_ Node16 : 24|1@0+ (1,0) [0|1] "-" ACM,AMP,EMCM,ESEM,ETM,HMSM,IPC,LBSS,RBSS,TBM,TTM
 SG_ Node17 : 25|1@0+ (1,0) [0|1] "-" ACM,AMP,EMCM,ESEM,ETM,HMSM,IPC,LBSS,RBSS,TBM,TTM
 SG_ Node18 : 26|1@0+ (1,0) [0|1] "-" ACM,AMP,EMCM,ESEM,ETM,HMSM,IPC,LBSS,RBSS,TBM,TTM
 SG_ Node19 : 27|1@0+ (1,0) [0|1] "-" ACM,AMP,EMCM,ESEM,ETM,HMSM,IPC,LBSS,RBSS,TBM,TTM
 SG_ Node2 : 42|1@0+ (1,0) [0|1] "-" ACM,AMP,EMCM,ESEM,ETM,HMSM,IPC,LBSS,RBSS,TBM,TTM
 SG_ Node20 : 28|1@0+ (1,0) [0|1] "-" ACM,AMP,EMCM,ESEM,ETM,HMSM,IPC,LBSS,RBSS,TBM,TTM
 SG_ Node21 : 29|1@0+ (1,0) [0|1] "-" ACM,AMP,EMCM,ESEM,ETM,HMSM,IPC,LBSS,RBSS,TBM,TTM
 SG_ Node22 : 30|1@0+ (1,0) [0|1] "-" ACM,AMP,EMCM,ESEM,ETM,HMSM,IPC,LBSS,RBSS,TBM,TTM
 SG_ Node23 : 31|1@0+ (1,0) [0|1] "-" ACM,AMP,EMCM,ESEM,ETM,HMSM,IPC,LBSS,RBSS,TBM,TTM
 SG_ Node24 : 16|1@0+ (1,0) [0|1] "-" ACM,AMP,EMCM,ESEM,ETM,HMSM,IPC,LBSS,RBSS,TBM,TTM
 SG_ Node25 : 17|1@0+ (1,0) [0|1] "-" ACM,AMP,EMCM,ESEM,ETM,HMSM,IPC,LBSS,RBSS,TBM,TTM
 SG_ Node26 : 18|1@0+ (1,0) [0|1] "-" ACM,AMP,EMCM,ESEM,ETM,HMSM,IPC,LBSS,RBSS,TBM,TTM
 SG_ Node27 : 19|1@0+ (1,0) [0|1] "-" ACM,AMP,EMCM,ESEM,ETM,HMSM,IPC,LBSS,RBSS,TBM,TTM
 SG_ Node28 : 20|1@0+ (1,0) [0|1] "-" ACM,AMP,EMCM,ESEM,ETM,HMSM,IPC,LBSS,RBSS,TBM,TTM
 SG_ Node29 : 21|1@0+ (1,0) [0|1] "-" ACM,AMP,EMCM,ESEM,ETM,HMSM,IPC,LBSS,RBSS,TBM,TTM
 SG_ Node3 : 43|1@0+ (1,0) [0|1] "-" ACM,AMP,EMCM,ESEM,ETM,HMSM,IPC,LBSS,RBSS,TBM,TTM
 SG_ Node30 : 22|1@0+ (1,0) [0|1] "-" ACM,AMP,EMCM,ESEM,ETM,HMSM,IPC,LBSS,RBSS,TBM,TTM
 SG_ Node31 : 23|1@0+ (1,0) [0|1] "-" ACM,AMP,EMCM,ESEM,ETM,HMSM,IPC,LBSS,RBSS,TBM,TTM
 SG_ Node4 : 44|1@0+ (1,0) [0|1] "-" ACM,AMP,EMCM,ESEM,ETM,HMSM,IPC,LBSS,RBSS,TBM,TTM
 SG_ Node5 : 45|1@0+ (1,0) [0|1] "-" ACM,AMP,EMCM,ESEM,ETM,HMSM,IPC,LBSS,RBSS,TBM,TTM
 SG_ Node6 : 46|1@0+ (1,0) [0|1] "-" ACM,AMP,EMCM,ESEM,ETM,HMSM,IPC,LBSS,RBSS,TBM,TTM
 SG_ Node7 : 47|1@0+ (1,0) [0|1] "-" ACM,AMP,EMCM,ESEM,ETM,HMSM,IPC,LBSS,RBSS,TBM,TTM
 SG_ Node8 : 32|1@0+ (1,0) [0|1] "-" ACM,AMP,EMCM,ESEM,ETM,HMSM,IPC,LBSS,RBSS,TBM,TTM
 SG_ Node9 : 33|1@0+ (1,0) [0|1] "-" ACM,AMP,EMCM,ESEM,ETM,HMSM,IPC,LBSS,RBSS,TBM,TTM
 SG_ P_ES : 13|1@0+ (1,0) [0|1] "-" ACM,AMP,EMCM,ESEM,ETM,HMSM,IPC,LBSS,RBSS,TBM,TTM
 SG_ SystemCommand : 9|2@0+ (1,0) [0|3] "-" ACM,AMP,EMCM,ESEM,ETM,HMSM,IPC,LBSS,RBSS,TBM,TTM
 SG_ Zero_byte_BCM : 7|8@0+ (1,0) [0|0] "-" ACM,AMP,EMCM,ESEM,ETM,HMSM,IPC,LBSS,RBSS,TBM,TTM

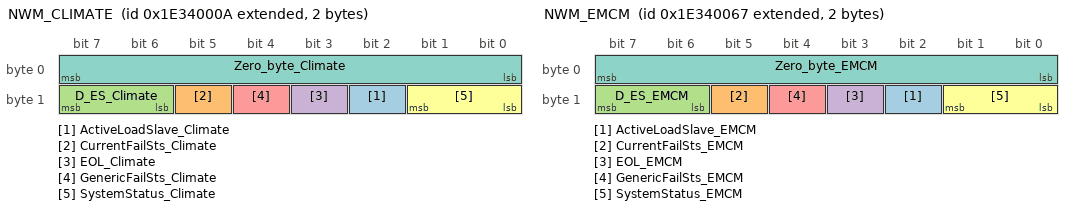
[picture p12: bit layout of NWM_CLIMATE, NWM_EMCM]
BO_ 2654208010 NWM_CLIMATE: 2 ACM
 SG_ ActiveLoadSlave_Climate : 10|1@0+ (1,0) [0|1] "-" BCM
 SG_ CurrentFailSts_Climate : 13|1@0+ (1,0) [0|1] "-" BCM
 SG_ D_ES_Climate : 15|2@0+ (1,0) [0|3] "-" Vector__XXX
 SG_ EOL_Climate : 11|1@0+ (1,0) [0|1] "-" BCM
 SG_ GenericFailSts_Climate : 12|1@0+ (1,0) [0|1] "-" BCM
 SG_ SystemStatus_Climate : 9|2@0+ (1,0) [0|3] "-" BCM
 SG_ Zero_byte_Climate : 7|8@0+ (1,0) [0|0] "-" BCM

BO_ 2654208103 NWM_EMCM: 2 EMCM
 SG_ ActiveLoadSlave_EMCM : 10|1@0+ (1,0) [0|1] "-" BCM
 SG_ CurrentFailSts_EMCM : 13|1@0+ (1,0) [0|1] "-" BCM
 SG_ D_ES_EMCM : 15|2@0+ (1,0) [0|3] "-" Vector__XXX
 SG_ EOL_EMCM : 11|1@0+ (1,0) [0|1] "-" BCM
 SG_ GenericFailSts_EMCM : 12|1@0+ (1,0) [0|1] "-" BCM
 SG_ SystemStatus_EMCM : 9|2@0+ (1,0) [0|3] "-" BCM
 SG_ Zero_byte_EMCM : 7|8@0+ (1,0) [0|0] "-" BCM

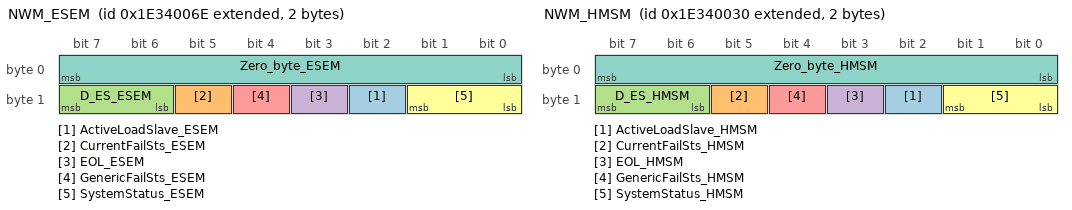
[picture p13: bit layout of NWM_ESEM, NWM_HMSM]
BO_ 2654208110 NWM_ESEM: 2 ESEM
 SG_ ActiveLoadSlave_ESEM : 10|1@0+ (1,0) [0|1] "-" BCM
 SG_ CurrentFailSts_ESEM : 13|1@0+ (1,0) [0|1] "-" BCM
 SG_ D_ES_ESEM : 15|2@0+ (1,0) [0|3] "-" Vector__XXX
 SG_ EOL_ESEM : 11|1@0+ (1,0) [0|1] "-" BCM
 SG_ GenericFailSts_ESEM : 12|1@0+ (1,0) [0|1] "-" BCM
 SG_ SystemStatus_ESEM : 9|2@0+ (1,0) [0|3] "-" BCM
 SG_ Zero_byte_ESEM : 7|8@0+ (1,0) [0|0] "-" BCM

BO_ 2654208048 NWM_HMSM: 2 HMSM
 SG_ ActiveLoadSlave_HMSM : 10|1@0+ (1,0) [0|1] "-" BCM
 SG_ CurrentFailSts_HMSM : 13|1@0+ (1,0) [0|1] "-" BCM
 SG_ D_ES_HMSM : 15|2@0+ (1,0) [0|3] "-" Vector__XXX
 SG_ EOL_HMSM : 11|1@0+ (1,0) [0|1] "-" BCM
 SG_ GenericFailSts_HMSM : 12|1@0+ (1,0) [0|1] "-" BCM
 SG_ SystemStatus_HMSM : 9|2@0+ (1,0) [0|3] "-" BCM
 SG_ Zero_byte_HMSM : 7|8@0+ (1,0) [0|0] "-" BCM

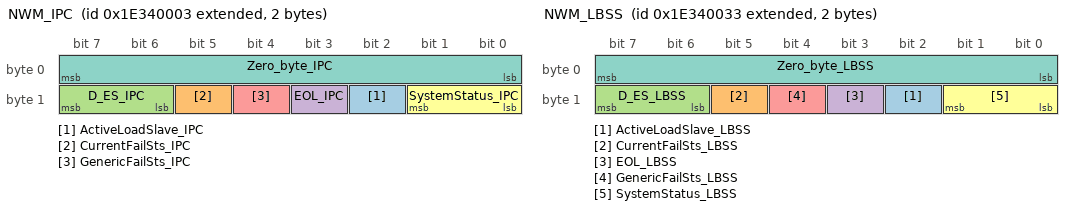
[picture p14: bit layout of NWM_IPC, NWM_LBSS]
BO_ 2654208003 NWM_IPC: 2 IPC
 SG_ ActiveLoadSlave_IPC : 10|1@0+ (1,0) [0|1] "-" BCM
 SG_ CurrentFailSts_IPC : 13|1@0+ (1,0) [0|1] "-" BCM
 SG_ D_ES_IPC : 15|2@0+ (1,0) [0|3] "-" Vector__XXX
 SG_ EOL_IPC : 11|1@0+ (1,0) [0|1] "-" BCM
 SG_ GenericFailSts_IPC : 12|1@0+ (1,0) [0|1] "-" BCM
 SG_ SystemStatus_IPC : 9|2@0+ (1,0) [0|3] "-" BCM
 SG_ Zero_byte_IPC : 7|8@0+ (1,0) [0|0] "-" BCM

BO_ 2654208051 NWM_LBSS: 2 LBSS
 SG_ ActiveLoadSlave_LBSS : 10|1@0+ (1,0) [0|1] "-" BCM
 SG_ CurrentFailSts_LBSS : 13|1@0+ (1,0) [0|1] "-" BCM
 SG_ D_ES_LBSS : 15|2@0+ (1,0) [0|3] "-" Vector__XXX
 SG_ EOL_LBSS : 11|1@0+ (1,0) [0|1] "-" BCM
 SG_ GenericFailSts_LBSS : 12|1@0+ (1,0) [0|1] "-" BCM
 SG_ SystemStatus_LBSS : 9|2@0+ (1,0) [0|3] "-" BCM
 SG_ Zero_byte_LBSS : 7|8@0+ (1,0) [0|0] "-" BCM

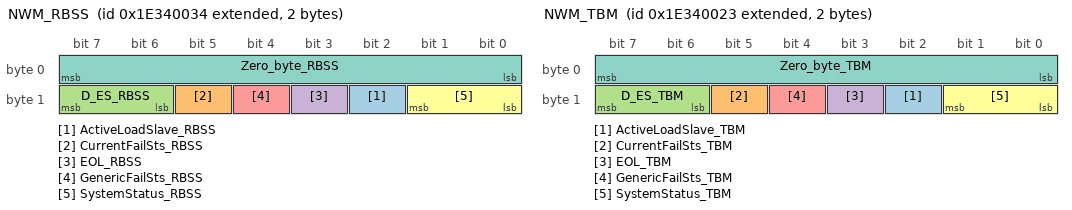
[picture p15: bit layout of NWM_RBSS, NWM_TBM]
BO_ 2654208052 NWM_RBSS: 2 RBSS
 SG_ ActiveLoadSlave_RBSS : 10|1@0+ (1,0) [0|1] "-" BCM
 SG_ CurrentFailSts_RBSS : 13|1@0+ (1,0) [0|1] "-" BCM
 SG_ D_ES_RBSS : 15|2@0+ (1,0) [0|3] "-" Vector__XXX
 SG_ EOL_RBSS : 11|1@0+ (1,0) [0|1] "-" BCM
 SG_ GenericFailSts_RBSS : 12|1@0+ (1,0) [0|1] "-" BCM
 SG_ SystemStatus_RBSS : 9|2@0+ (1,0) [0|3] "-" BCM
 SG_ Zero_byte_RBSS : 7|8@0+ (1,0) [0|0] "-" BCM

BO_ 2654208035 NWM_TBM: 2 TBM
 SG_ ActiveLoadSlave_TBM : 10|1@0+ (1,0) [0|1] "-" BCM
 SG_ CurrentFailSts_TBM : 13|1@0+ (1,0) [0|1] "-" BCM
 SG_ D_ES_TBM : 15|2@0+ (1,0) [0|3] "-" Vector__XXX
 SG_ EOL_TBM : 11|1@0+ (1,0) [0|1] "-" BCM
 SG_ GenericFailSts_TBM : 12|1@0+ (1,0) [0|1] "-" BCM
 SG_ SystemStatus_TBM : 9|2@0+ (1,0) [0|3] "-" BCM
 SG_ Zero_byte_TBM : 7|8@0+ (1,0) [0|0] "-" BCM

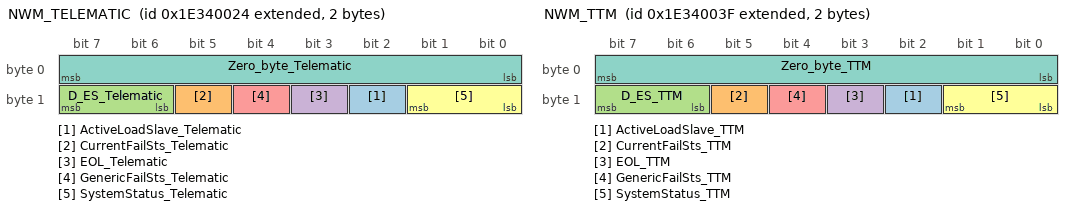
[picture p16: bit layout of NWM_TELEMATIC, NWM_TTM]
BO_ 2654208036 NWM_TELEMATIC: 2 ETM
 SG_ ActiveLoadSlave_Telematic : 10|1@0+ (1,0) [0|1] "-" BCM
 SG_ CurrentFailSts_Telematic : 13|1@0+ (1,0) [0|1] "-" BCM
 SG_ D_ES_Telematic : 15|2@0+ (1,0) [0|3] "-" Vector__XXX
 SG_ EOL_Telematic : 11|1@0+ (1,0) [0|1] "-" BCM
 SG_ GenericFailSts_Telematic : 12|1@0+ (1,0) [0|1] "-" BCM
 SG_ SystemStatus_Telematic : 9|2@0+ (1,0) [0|3] "-" BCM
 SG_ Zero_byte_Telematic : 7|8@0+ (1,0) [0|0] "-" BCM

BO_ 2654208063 NWM_TTM: 2 TTM
 SG_ ActiveLoadSlave_TTM : 10|1@0+ (1,0) [0|1] "-" BCM
 SG_ CurrentFailSts_TTM : 13|1@0+ (1,0) [0|1] "-" BCM
 SG_ D_ES_TTM : 15|2@0+ (1,0) [0|3] "-" Vector__XXX
 SG_ EOL_TTM : 11|1@0+ (1,0) [0|1] "-" BCM
 SG_ GenericFailSts_TTM : 12|1@0+ (1,0) [0|1] "-" BCM
 SG_ SystemStatus_TTM : 9|2@0+ (1,0) [0|3] "-" BCM
 SG_ Zero_byte_TTM : 7|8@0+ (1,0) [0|0] "-" BCM

BO_ 950 PARK_INFO: 6 BCM
 SG_ Alert_CHF : 12|3@0+ (1,0) [0|7] "-" ETM
 SG_ Alert_CHR : 5|3@0+ (1,0) [0|7] "-" ETM
 SG_ Alert_LHF : 9|3@0+ (1,0) [0|7] "-" ETM
 SG_ Alert_LHR : 2|3@0+ (1,0) [0|7] "-" ETM
 SG_ Alert_RHF : 22|3@0+ (1,0) [0|7] "-" ETM
 SG_ Alert_RHR : 15|3@0+ (1,0) [0|7] "-" ETM
 SG_ ChimeActivation_LHF : 36|1@0+ (1,0) [0|1] "-" AMP,ETM,IPC
 SG_ ChimeActivation_LHR : 38|1@0+ (1,0) [0|1] "-" AMP,ETM,IPC
 SG_ ChimeActivation_RHF : 37|1@0+ (1,0) [0|1] "-" AMP,ETM,IPC
 SG_ ChimeActivation_RHR : 39|1@0+ (1,0) [0|1] "-" AMP,ETM,IPC
 SG_ ChimeRepetitionRate_Front : 47|4@0+ (1,0) [0|15] "Hz" AMP,ETM,IPC
 SG_ ChimeRepetitionRate_Rear : 43|4@0+ (1,0) [0|15] "Hz" AMP,ETM,IPC
 SG_ ChimeType_Front : 33|2@0+ (1,0) [0|3] "-" AMP,ETM
 SG_ ChimeType_Rear : 35|2@0+ (1,0) [0|3] "-" AMP,ETM,IPC
 SG_ DisplayActivation : 6|1@0+ (1,0) [0|1] "-" ETM
 SG_ Graphic_CHF : 29|2@0+ (1,0) [0|3] "-" ETM
 SG_ Graphic_CHR : 19|2@0+ (1,0) [0|3] "-" ETM
 SG_ Graphic_LHF : 27|2@0+ (1,0) [0|3] "-" ETM
 SG_ Graphic_LHR : 17|2@0+ (1,0) [0|3] "-" ETM
 SG_ Graphic_RHF : 25|2@0+ (1,0) [0|3] "-" ETM
 SG_ Graphic_RHR : 31|2@0+ (1,0) [0|3] "-" ETM

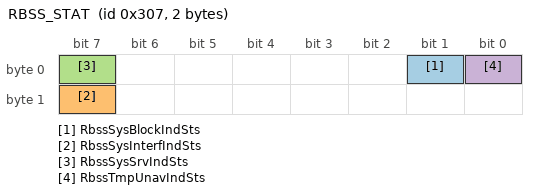
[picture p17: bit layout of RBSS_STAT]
BO_ 775 RBSS_STAT: 2 RBSS
 SG_ RbssSysBlockIndSts : 1|1@0+ (1,0) [0|1] "" LBSS
 SG_ RbssSysInterfIndSts : 15|1@0+ (1,0) [0|1] "" LBSS
 SG_ RbssSysSrvIndSts : 7|1@0+ (1,0) [0|1] "" LBSS
 SG_ RbssTmpUnavIndSts : 0|1@0+ (1,0) [0|1] "" LBSS

BO_ 1890 SERVICEINFO2: 6 IPC
 SG_ DaysToService : 22|9@0+ (1,0) [0|366] "day" ETM
 SG_ DistanceToService : 7|17@0+ (1,0) [0|131071] "km_or_mi" ETM

BO_TX_BU_ 2564554481 : BCM,DIAG_TEST;
BO_TX_BU_ 2564457457 : BCM,DIAG_TEST;
BO_TX_BU_ 2564462833 : BCM,DIAG_TEST;
BO_TX_BU_ 2564459249 : BCM,DIAG_TEST;
BO_TX_BU_ 2564459505 : BCM,DIAG_TEST;
BO_TX_BU_ 2564473585 : BCM,DIAG_TEST;
BO_TX_BU_ 2564449009 : BCM,DIAG_TEST;
BO_TX_BU_ 2564449777 : BCM,DIAG_TEST;
BO_TX_BU_ 2564474609 : BCM,DIAG_TEST;
BO_TX_BU_ 2564458481 : BCM,DIAG_TEST;
BO_TX_BU_ 2564442865 : BCM,DIAG_TEST;

CM_ "Project_952_ProjectStandard_B-CAN [07338_Alfa]";
CM_ SG_ 1474 PanicModeActive "Panic Status";
CM_ SG_ 160 BCMFpsCommand "The signal is used to command the FPS strategy actuation";
CM_ SG_ 160 BCMFpsConfirm "The signal is used to confirm the FPS strategy command";
CM_ SG_ 160 BCMFpsFailSts "This signal is used to give information of a fault present on the FPS sensing device .";
CM_ SG_ 160 WasherLevelSts "This signal  indicates the washer level status (High or low).";
CM_ SG_ 134 FPS_Status_Request "The signal is used to request the status of  FPS system.";
CM_ SG_ 1894 CMP_DIR "Compass direction";
CM_ SG_ 1894 CMP_DIR_RAW "Compass direction raw";
CM_ SG_ 1894 IN_CAL_MD "In Calibration Mode";
CM_ SG_ 1894 VAR_VAL "COM Variance Value";
CM_ SG_ 1478 AUD_LVLSts "Audio level";
CM_ SG_ 1478 BAL_LVLSts "Balance level [ P = right; N = left ]";
CM_ SG_ 1478 BASS_LVLSts "Bass range level";
CM_ SG_ 1478 DSS_ONSts "Driver Surround Sound On/Off";
CM_ SG_ 1478 FD_LVLSts "Fade level [ P = right; N = left ]";
CM_ SG_ 1478 INFO1_AUD_ACT "Information source 1 audio active";
CM_ SG_ 1478 INFO1_AUD_LEVEL "Information source 1 audio level";
CM_ SG_ 1478 INFO1_AUD_TYPE "Mono Audio Control Enable";
CM_ SG_ 1478 INFO2_AUD_ACT "Information source 2 audio active";
CM_ SG_ 1478 INFO2_AUD_LEVEL "Information source 2 audio level";
CM_ SG_ 1478 INFO2_AUD_TYPE "Mono Audio Control Enable";
CM_ SG_ 1478 MID_LVLSts "Mid range level";
CM_ SG_ 1478 SCV_LVLSts "Speed controlled volume level";
CM_ SG_ 1478 TREB_LVLSts "Treble range level";
CM_ SG_ 2564554481 N_PDU "This signal is used for diagnostic purposes";
CM_ SG_ 2564457457 N_PDU "This signal is used for diagnostic purposes";
CM_ SG_ 2564462833 N_PDU "This signal is used for diagnostic purposes";
CM_ SG_ 2564459249 N_PDU "This signal is used for diagnostic purposes";
CM_ SG_ 2564459505 N_PDU "This signal is used for diagnostic purposes";
CM_ SG_ 2564473585 N_PDU "This signal is used for diagnostic purposes";
CM_ SG_ 2564449009 N_PDU "This signal is used for diagnostic purposes";
CM_ SG_ 2564449777 N_PDU "This signal is used for diagnostic purposes";
CM_ SG_ 2564474609 N_PDU "-";
CM_ SG_ 2564458481 N_PDU "This signal is used for diagnostic purposes";
CM_ SG_ 2564442865 N_PDU "This signal is used for diagnostic purposes";
CM_ SG_ 2564485507 N_PDU "-";
CM_ SG_ 2564485528 N_PDU "This signal is used for diagnostic purposes";
CM_ SG_ 2564485514 N_PDU "-";
CM_ SG_ 2564485515 N_PDU "This signal is used for diagnostic purposes";
CM_ SG_ 2564485570 N_PDU "-";
CM_ SG_ 2564485474 N_PDU "-";
CM_ SG_ 2564485477 N_PDU "-";
CM_ SG_ 2564485574 N_PDU "-";
CM_ SG_ 2564485511 N_PDU "This signal is used for diagnostic purposes";
CM_ SG_ 2564485450 N_PDU "-";
CM_ SG_ 140 Text_Available "This signal is used to give acknowledge about the presence of Text or Numbers or both on ETM display";
CM_ SG_ 140 TP_Enable_Click "This signal is used to give acknowledge about Click function (enable/disable)";
CM_ SG_ 140 TP_Enable_DoubleClick "This signal is used to give acknowledge about Double Click function (enable/disable)";
CM_ SG_ 140 TP_Enable_Longpress "This signal is used to give acknowledge about Long Press function (enable/disable)";
CM_ SG_ 140 TP_Enable_Pan "This signal is used to give acknowledge about Pan function (enable/disable)";
CM_ SG_ 140 TP_Enable_Rotate "This signal is used to give acknowledge about Rotate function (enable/disable)";
CM_ SG_ 140 TP_Enable_Scroll "This signal is used to give acknowledge about Scroll function (enable/disable)";
CM_ SG_ 140 TP_Enable_Swipe "This signal is used to give acknowledge about Swipe function (enable/disable)";
CM_ SG_ 140 TP_Enable_Zoom "This signal is used to give acknowledge about Zoom function (enable/disable)";
CM_ SG_ 856 Home_Button "This signal is used to give information about the Release/Press of Home Button";
CM_ SG_ 856 Knob_Capacitive_Switch "This signal is used to give information about the distance of the hand from the knob";
CM_ SG_ 856 Knob_deflection_push "This signal is used to give information about the knob push";
CM_ SG_ 856 Knob_Encoder_Direction "This signal is used to give information about numer of clockwise";
CM_ SG_ 856 Knob_Encoder_Val "This signal is used to give information about the CW and CCW (clockwise; counterclockwise incremental)";
CM_ SG_ 856 Option_Button "This signal is used to give information about the Release/Press status";
CM_ SG_ 856 Rotary_Volume_Dir "This signal is used to give information about the number of steps";
CM_ SG_ 856 Rotary_Volume_Val "This signal is used to give information about the CW or CCW";
CM_ SG_ 856 SeekMinus "This signal is used to give information about the Release/Press of Seek - button";
CM_ SG_ 856 SeekPlus "This signal is used to give information about the Release/Press of Seek + button";
CM_ SG_ 142 Text_Available "This signal is used to give acknowledge about the presence of Text or Numbers or both on ETM display";
CM_ SG_ 142 TP_Enable_Click "This signal is used to give acknowledge about Click function (enable/disable)";
CM_ SG_ 142 TP_Enable_DoubleClick "This signal is used to give acknowledge about Double Click function (enable/disable)";
CM_ SG_ 142 TP_Enable_Longpress "This signal is used to give acknowledge about Long Press function (enable/disable)";
CM_ SG_ 142 TP_Enable_Pan "This signal is used to give acknowledge about Pan function (enable/disable)";
CM_ SG_ 142 TP_Enable_Rotate "This signal is used to give acknowledge about Rotate function (enable/disable)";
CM_ SG_ 142 TP_Enable_Scroll "This signal is used to give acknowledge about Scroll function (enable/disable)";
CM_ SG_ 142 TP_Enable_Swipe "This signal is used to give acknowledge about Swipe function (enable/disable)";
CM_ SG_ 142 TP_Enable_Zoom "This signal is used to give acknowledge about Zoom function (enable/disable)";
CM_ SG_ 852 AHBFeature "This signal indicates the Auto High Beam Feature status";
CM_ SG_ 852 ALBFeature "This signal indicates the Auto Low Beam Feature status";
CM_ SG_ 852 FHeatedWindowSts "Used to indicate the Front heated window activation/deactivation status";
CM_ SG_ 852 L_TurnLightActivationSts "Request of Left Turn Lights activation";
CM_ SG_ 852 R_TurnLightActivationSts "Request of Right Turn Lights activation";
CM_ SG_ 852 RHeatedWindowSts "Used to indicate the Rear heated window activation/deactivation status";
CM_ SG_ 852 StopLightSts "Request of Stop Lights activation";
CM_ SG_ 2147485498 GPS_POS1_Lat "GPS Latitude (- means south)";
CM_ SG_ 2147485498 GPS_POS1_Long "GPS Longitude (- means west)";
CM_ SG_ 2147485500 GPS_POS2_Alt "GPS Altitude";
CM_ SG_ 2147485500 GPS_POS2_Ellip "GPS Ellipsoid Height";
CM_ SG_ 2147485500 GPS_POS2_Head "GPS Heading";
CM_ SG_ 2147485500 GPS_POS2_Vel "GPS Velocity";
CM_ SG_ 2147485502 GPS_POS3_Date_Day "GPS date day";
CM_ SG_ 2147485502 GPS_POS3_Date_Hour "GPS date hour";
CM_ SG_ 2147485502 GPS_POS3_Date_Minutes "GPS date minutes";
CM_ SG_ 2147485502 GPS_POS3_Date_Month "GPS date month";
CM_ SG_ 2147485502 GPS_POS3_Date_Seconds "GPS date seconds";
CM_ SG_ 2147485502 GPS_POS3_Date_Year "GPS date year";
CM_ SG_ 2147485506 GPS_POS5_Fix "GPS fix";
CM_ SG_ 2147485506 GPS_POS5_Hdop "GPS Hdop";
CM_ SG_ 2147485506 GPS_POS5_Pdop "GPS Pdop";
CM_ SG_ 2147485506 GPS_POS5_Trck_Sat "GPS Tracked Satellites";
CM_ SG_ 2147485506 GPS_POS5_Vdop "GPS Vdop";
CM_ SG_ 2147485506 GPS_POS5_Vsbl_Sat "GPS Visible Satellites";
CM_ SG_ 1270 AHBFault "HALF sends to the BCM the fault condition";
CM_ SG_ 1270 SensorBlinded "This signal indicates the HALF state";
CM_ SG_ 1468 AmbientLightingLevel "This signal is used to give information about the Ambient Lighting Level selected";
CM_ SG_ 1468 AudioRepetition "This signal is used to give information about the Audio Repetition selected";
CM_ SG_ 1468 AutoHighBeamEnable "This signal is used to give information about the Auto High Beam feature selected";
CM_ SG_ 1468 AutomaticResetTripB "This signal is used to give information about the Automatic Reset of Trip B selected";
CM_ SG_ 1468 AutoParkBrake "This signal is used to give information about the Auto Park Brake selected";
CM_ SG_ 1468 AutoRelock "This signal is used to give information about the Auto Relock feature selected";
CM_ SG_ 1468 BSDEnable "This signal is used to give information about the Blind Spot Alert feature selected";
CM_ SG_ 1468 ConsumptionUnit "This signal is used to give information about the Consumption Unit selected";
CM_ SG_ 1468 CorneringEnable "This signal is used to give information about the Cornering Lights selected";
CM_ SG_ 1468 DistanceUnit "This signal is used to give information about the Distance Unit selected";
CM_ SG_ 1468 DRLEnable "This signal is used to give information about the DRL feature selected";
CM_ SG_ 1468 ExternalLightSensorLevel "This signal is used to give information about the External Light Sensor Level selected";
CM_ SG_ 1468 GreetingLightsEnable "This signal is used to give information about the Greeting Lights selected";
CM_ SG_ 1468 HourMode "This signal is used to give information about the Hour Mode selected.";
CM_ SG_ 1468 LanguageSelection "This signal is used to give information about the Language selected";
CM_ SG_ 1468 NavRepetition "This signal is used to give information about the Navigation Repetition selected";
CM_ SG_ 1468 PamAlertMode "This signal is used to give information about the PAM Alert Mode selected";
CM_ SG_ 1468 PamChimeVolumeFront "This signal is used to give information about the PAM  Chime Volume selected";
CM_ SG_ 1468 PamChimeVolumeRear "This signal is used to give information about the PAM 8Ch Chime Volume selected";
CM_ SG_ 1468 PassiveEntry "This signal is used to give information about the Passive Entry selected";
CM_ SG_ 1468 PhoneRepetition "This signal is used to give information about the Phone Repetition selected";
CM_ SG_ 1468 RemoteDoorUnlock "This signal is used to give information about the Remote Door Unlock selected";
CM_ SG_ 1468 Sdw "This signal is used to give information about the Side Distance Warning feature selected";
CM_ SG_ 1468 SdwChimeVolume "This signal is used to give information about the SDW Chime Volume selected";
CM_ SG_ 1468 SoundHornLock "This signal is used to give information about the Sound Horn with Lock selected";
CM_ SG_ 1468 SoundHornRemoteStart "This signal is used to give information about the Sound Horn with Remote Start selected";
CM_ SG_ 1468 SpeedLockDoorEnable "This signal is used to give information about the Autoclose feature selected";
CM_ SG_ 1468 TelematicSetupACK "Used to give information about the acknowledge of the requested setup changes by telematic module.";
CM_ SG_ 1468 TemperatureUnit "This signal is used to give information about the Temperature Unit selected";
CM_ SG_ 1486 AutoUnlockDoorExit "This signal is used to give information about the Auto Unlock Door on Exit feature selected";
CM_ SG_ 1486 BrakeService "This signal is used to give information about the Brake Service selected";
CM_ SG_ 1486 BuzzerVolume "This signal is used to give information about the Buzzer Volume function Status";
CM_ SG_ 1486 CalibrationSetup "This signal is used to give information about the Calibration Setup of the Compass function";
CM_ SG_ 1486 EPB_Maintenance_Fdbk "It indicates the HMI state of the EPB Functionality for the Maintenance Procedure";
CM_ SG_ 1486 EPB_MaintenanceMode "This signal is used to give information about the Maintenance Mode feature selected";
CM_ SG_ 1486 FlashLightWLock "This signal is used to give information about the Flash Light With Lock selected";
CM_ SG_ 1486 FrontPassengerAirBag "This signal is used to give information about the Front Passenger Airbag selected";
CM_ SG_ 1486 FSFCWPlusActivationMode "This signal is used to give information about the FSFCW Activation Mode setting";
CM_ SG_ 1486 FSFCWPlusSetting "This signal is used to give information about the FSFCW setting";
CM_ SG_ 1486 HeadlightsOffDelay "This signal is used to give information about the Headlights Off Delay selected";
CM_ SG_ 1486 HHDisabling "This signal is used to give information about the Hill Holder selected";
CM_ SG_ 1486 LDW_Sensibility "This signal is used to give information about the LDW Sensibility selected";
CM_ SG_ 1486 SeltBeltReminder "This signal is used to give information about the Selt Belt Reminder selected";
CM_ SG_ 1486 SpeedLimitSet "This signal is used to give information about the Speed warning selected";
CM_ SG_ 1486 SpeedLimitSts "This signal is used to give information about the Speed Limit function Status";
CM_ SG_ 1486 TyrePressureUnit "This signal is used to give information about the Tyre Pressure Unit selected";
CM_ SG_ 1486 VarianceSet "This signal is used to give information about the Variance Set of the Compass function";
CM_ SG_ 773 LbssSysBlockIndSts "LBSS system indication status";
CM_ SG_ 773 LbssSysInterfIndSts "LBSS system interference indication status";
CM_ SG_ 773 LbssSysSrvIndSts "LBSS system service indication status";
CM_ SG_ 773 LbssTmpUnavIndSts "LBSS system Temporarily unavailable indication status";
CM_ SG_ 950 Alert_CHF "This signal indicates which arc shall be displayed in the central hand, front position of the car graphics.";
CM_ SG_ 950 Alert_CHR "This signal indicates which arc shall be displayed in the central hand, rear position of the car graphics.";
CM_ SG_ 950 Alert_LHF "This signal indicates which arc shall be displayed in the left hand, front position of the car graphics.";
CM_ SG_ 950 Alert_LHR "This signal indicates which arc shall be displayed in the left hand, rear position of the car graphics.";
CM_ SG_ 950 Alert_RHF "This signal indicates which arc shall be displayed in the right hand, front position of the car graphics.";
CM_ SG_ 950 Alert_RHR "This signal indicates which arc shall be displayed in the right hand, rear position of the car graphics.";
CM_ SG_ 950 ChimeActivation_LHF "This signal indicates the chime activation request for the left hand, front audio speaker, or rear hardwired buzzer.";
CM_ SG_ 950 ChimeActivation_LHR "This signal indicates the chime activation request for the left hand, rear audio speaker, or rear hardwired buzzer.";
CM_ SG_ 950 ChimeActivation_RHF "This signal indicates the chime activation request for the right hand, front audio speaker, or rear hardwired buzzer.";
CM_ SG_ 950 ChimeActivation_RHR "This signal indicates the chime activation request for the right hand, rear audio speaker, or rear hardwired buzzer.";
CM_ SG_ 950 ChimeRepetitionRate_Front "This signal indicates the repetition rate for the front audio speakers.";
CM_ SG_ 950 ChimeRepetitionRate_Rear "This signal indicates the repetition rate for the rear audio speakers.";
CM_ SG_ 950 ChimeType_Front "This signal indicates the Chime Type for the front audio speakers.";
CM_ SG_ 950 ChimeType_Rear "This signal indicates the Chime Type for the rear audio speakers.";
CM_ SG_ 950 DisplayActivation "This signal indicates the request to display the car graphics layout on the IPC/EVIC screen.";
CM_ SG_ 950 Graphic_CHF "This signal indicates the flash rate of the arc displayed in the central hand, front position of the car graphics.";
CM_ SG_ 950 Graphic_CHR "This signal indicates the flash rate of the arc displayed in the central hand, rear position of the car graphics.";
CM_ SG_ 950 Graphic_LHF "This signal indicates the flash rate of the arc displayed in the left hand, front position of the car graphics.";
CM_ SG_ 950 Graphic_LHR "This signal indicates the flash rate of the arc displayed in the left hand, rear position of the car graphics.";
CM_ SG_ 950 Graphic_RHF "This signal indicates the flash rate of the arc displayed in the right hand, front position of the car graphics.";
CM_ SG_ 950 Graphic_RHR "This signal indicates the flash rate of the arc displayed in the right hand, rear position of the car graphics.";
CM_ SG_ 775 RbssSysBlockIndSts "RBSS system block indication status";
CM_ SG_ 775 RbssSysInterfIndSts "RBSS system interference indication status";
CM_ SG_ 775 RbssSysSrvIndSts "RBSS system indication status";
CM_ SG_ 775 RbssTmpUnavIndSts "RBSS system temporarily unavailable indication status";
CM_ SG_ 1890 DaysToService "Used to give information about the missing days for the next vehicle service.";
CM_ SG_ 1890 DistanceToService "Used to give information about the missing distance for the next vehicle service.";

BA_DEF_ SG_ "Accuracy" STRING ;
BA_DEF_ SG_ "Event trans." ENUM "Yes","No";
BA_DEF_ SG_ "GenSigStartValue" INT 0 2147483647;
BA_DEF_ SG_ "GenSigInactiveValue" INT 0 2147483647;
BA_DEF_ SG_ "GenSigSendType" ENUM "NotUsed","OnWrite","OnWriteWithRepetition","OnChange","OnChangeWithRepetition","IfActive","IfActiveWithRepetition","NoSigSendType";
BA_DEF_ BO_ "DiagRequest" ENUM "No","Yes";
BA_DEF_ BO_ "Period [ms]" INT 0 65535;
BA_DEF_ BO_ "Type" ENUM "P","C","PE","COC","PE_Cntrl","E","E_Cntrl","OC","S","BAF","DC","EM","MM","-";
BA_DEF_ BO_ "DiagResponse" ENUM "No","Yes";
BA_DEF_ BO_ "NmMessage" ENUM "No","Yes";
BA_DEF_ BO_ "GenMsgSendType" ENUM "Cyclic","NotUsed","NotUsed","NotUsed","NotUsed","NotUsed","NotUsed","NotUsed","NoMsgSendType";
BA_DEF_ BO_ "GenMsgTimeoutTime" INT 0 10000;
BA_DEF_ BO_ "GenMsgNrOfRepetition" INT 0 255;
BA_DEF_ BO_ "GenMsgILSupport" ENUM "No","Yes";
BA_DEF_ BO_ "GenMsgStartDelayTime" INT 0 65535;
BA_DEF_ BO_ "GenMsgCycleTimeFast" INT 0 65535;
BA_DEF_ BO_ "GenMsgCycleTime" INT 0 65535;
BA_DEF_ BO_ "GenMsgDelayTime" INT 0 65535;
BA_DEF_ BO_ "DiagState" ENUM "No","Yes";
BA_DEF_ BU_ "NodeLayerModules" STRING ;
BA_DEF_ BU_ "Description" STRING ;
BA_DEF_ BU_ "NmStationAddress" HEX 0 255;
BA_DEF_ BU_ "NmNode" ENUM "No","Yes";
BA_DEF_ BU_ "ILUsed" ENUM "No","Yes";
BA_DEF_ BU_ "NmNodeType" ENUM "kMaster","kSlave15","kSlave30","none";
BA_DEF_ BU_ "NwmNodeType" ENUM "kMaster","kSlave15","kSlave30","none";
BA_DEF_ BU_ "TpOwnSystemEcuNumber" HEX 0 255;
BA_DEF_ "Manufacturer" STRING ;
BA_DEF_ "NmType" STRING ;
BA_DEF_ "BusType" STRING ;
BA_DEF_ "Baudrate" INT 0 1000000;
BA_DEF_ "DBName" STRING ;
BA_DEF_ "Version" HEX 0 255;
BA_DEF_ "VersionWeek" INT 0 53;
BA_DEF_ "VersionYear" INT 0 99;
BA_DEF_DEF_ "Accuracy" "";
BA_DEF_DEF_ "Event trans." "No";
BA_DEF_DEF_ "GenSigStartValue" 0;
BA_DEF_DEF_ "GenSigInactiveValue" 0;
BA_DEF_DEF_ "GenSigSendType" "NoSigSendType";
BA_DEF_DEF_ "DiagRequest" "No";
BA_DEF_DEF_ "Period [ms]" 0;
BA_DEF_DEF_ "Type" "-";
BA_DEF_DEF_ "DiagResponse" "No";
BA_DEF_DEF_ "NmMessage" "No";
BA_DEF_DEF_ "GenMsgSendType" "NoMsgSendType";
BA_DEF_DEF_ "GenMsgTimeoutTime" 0;
BA_DEF_DEF_ "GenMsgNrOfRepetition" 0;
BA_DEF_DEF_ "GenMsgILSupport" "No";
BA_DEF_DEF_ "GenMsgStartDelayTime" 0;
BA_DEF_DEF_ "GenMsgCycleTimeFast" 0;
BA_DEF_DEF_ "GenMsgCycleTime" 0;
BA_DEF_DEF_ "GenMsgDelayTime" 0;
BA_DEF_DEF_ "DiagState" "No";
BA_DEF_DEF_ "NodeLayerModules" "Osek_TP.dll";
BA_DEF_DEF_ "Description" "";
BA_DEF_DEF_ "NmStationAddress" 0;
BA_DEF_DEF_ "NmNode" "Yes";
BA_DEF_DEF_ "ILUsed" "Yes";
BA_DEF_DEF_ "NmNodeType" "none";
BA_DEF_DEF_ "NwmNodeType" "none";
BA_DEF_DEF_ "TpOwnSystemEcuNumber" 0;
BA_DEF_DEF_ "Manufacturer" "Fiat";
BA_DEF_DEF_ "NmType" "";
BA_DEF_DEF_ "BusType" "CAN";
BA_DEF_DEF_ "Baudrate" 500000;
BA_DEF_DEF_ "DBName" "CAN";
BA_DEF_DEF_ "Version" 160;
BA_DEF_DEF_ "VersionWeek" 28;
BA_DEF_DEF_ "VersionYear" 15;
BA_ "NmType" "FIAT";
BA_ "Baudrate" 125000;
BA_ "DBName" "CAN-BH";
BA_ "Description" BU_ ACM "Automatic Control Module";
BA_ "NmStationAddress" BU_ ACM 10;
BA_ "NmNodeType" BU_ ACM 1;
BA_ "NwmNodeType" BU_ ACM 1;
BA_ "TpOwnSystemEcuNumber" BU_ ACM 152;
BA_ "Description" BU_ AMP "Amplifier";
BA_ "NmStationAddress" BU_ AMP 46;
BA_ "NmNodeType" BU_ AMP 2;
BA_ "NwmNodeType" BU_ AMP 2;
BA_ "TpOwnSystemEcuNumber" BU_ AMP 131;
BA_ "Description" BU_ BCM "Body Control Module";
BA_ "NmNodeType" BU_ BCM 0;
BA_ "NwmNodeType" BU_ BCM 0;
BA_ "TpOwnSystemEcuNumber" BU_ BCM 64;
BA_ "Description" BU_ DIAG_TEST "Diagnostic Tester";
BA_ "Description" BU_ EMCM "Entertainment Multimedia Control Module";
BA_ "NmStationAddress" BU_ EMCM 103;
BA_ "NmNodeType" BU_ EMCM 2;
BA_ "NwmNodeType" BU_ EMCM 2;
BA_ "TpOwnSystemEcuNumber" BU_ EMCM 138;
BA_ "Description" BU_ ESEM "Engine Sound Enhacement Module";
BA_ "NmStationAddress" BU_ ESEM 110;
BA_ "NmNodeType" BU_ ESEM 2;
BA_ "NwmNodeType" BU_ ESEM 2;
BA_ "TpOwnSystemEcuNumber" BU_ ESEM 139;
BA_ "Description" BU_ ETM "Entertainment Telematic Module";
BA_ "NmStationAddress" BU_ ETM 36;
BA_ "NmNodeType" BU_ ETM 2;
BA_ "NwmNodeType" BU_ ETM 2;
BA_ "TpOwnSystemEcuNumber" BU_ ETM 135;
BA_ "Description" BU_ HMSM "Heating and Memory Seat Module";
BA_ "NmStationAddress" BU_ HMSM 48;
BA_ "NmNodeType" BU_ HMSM 2;
BA_ "NwmNodeType" BU_ HMSM 2;
BA_ "TpOwnSystemEcuNumber" BU_ HMSM 194;
BA_ "Description" BU_ IPC "Instrument Panel Cluster";
BA_ "NmStationAddress" BU_ IPC 3;
BA_ "NmNodeType" BU_ IPC 2;
BA_ "NwmNodeType" BU_ IPC 2;
BA_ "TpOwnSystemEcuNumber" BU_ IPC 96;
BA_ "Description" BU_ LBSS "Left Blind  Spot Sensor";
BA_ "NmStationAddress" BU_ LBSS 51;
BA_ "NmNodeType" BU_ LBSS 1;
BA_ "NwmNodeType" BU_ LBSS 1;
BA_ "TpOwnSystemEcuNumber" BU_ LBSS 98;
BA_ "Description" BU_ RBSS "Right Blind Spot Sensor";
BA_ "NmStationAddress" BU_ RBSS 52;
BA_ "NmNodeType" BU_ RBSS 1;
BA_ "NwmNodeType" BU_ RBSS 1;
BA_ "TpOwnSystemEcuNumber" BU_ RBSS 101;
BA_ "Description" BU_ TBM "Telematic Box Module";
BA_ "NmStationAddress" BU_ TBM 35;
BA_ "NmNodeType" BU_ TBM 2;
BA_ "NwmNodeType" BU_ TBM 2;
BA_ "TpOwnSystemEcuNumber" BU_ TBM 198;
BA_ "Description" BU_ TTM "Trailer Tow Module";
BA_ "NmStationAddress" BU_ TTM 63;
BA_ "NmNodeType" BU_ TTM 2;
BA_ "NwmNodeType" BU_ TTM 2;
BA_ "TpOwnSystemEcuNumber" BU_ TTM 74;
BA_ "Period [ms]" BO_ 1884 1000;
BA_ "Type" BO_ 1884 1;
BA_ "GenMsgSendType" BO_ 1884 0;
BA_ "GenMsgTimeoutTime" BO_ 1884 2500;
BA_ "GenMsgILSupport" BO_ 1884 1;
BA_ "GenMsgCycleTime" BO_ 1884 1000;
BA_ "Period [ms]" BO_ 1474 1000;
BA_ "Type" BO_ 1474 3;
BA_ "GenMsgSendType" BO_ 1474 0;
BA_ "GenMsgILSupport" BO_ 1474 1;
BA_ "GenMsgStartDelayTime" BO_ 1474 500;
BA_ "GenMsgCycleTime" BO_ 1474 1000;
BA_ "GenMsgDelayTime" BO_ 1474 20;
BA_ "Type" BO_ 160 8;
BA_ "GenMsgTimeoutTime" BO_ 160 2500;
BA_ "GenMsgNrOfRepetition" BO_ 160 3;
BA_ "GenMsgILSupport" BO_ 160 1;
BA_ "GenMsgCycleTimeFast" BO_ 160 250;
BA_ "GenMsgDelayTime" BO_ 160 20;
BA_ "Type" BO_ 2651930624 8;
BA_ "GenMsgTimeoutTime" BO_ 2651930624 2500;
BA_ "GenMsgILSupport" BO_ 2651930624 1;
BA_ "Type" BO_ 2651930670 11;
BA_ "GenMsgTimeoutTime" BO_ 2651930670 2500;
BA_ "GenMsgILSupport" BO_ 2651930670 1;
BA_ "Type" BO_ 2651930634 11;
BA_ "GenMsgTimeoutTime" BO_ 2651930634 2500;
BA_ "GenMsgILSupport" BO_ 2651930634 1;
BA_ "Type" BO_ 2651930727 11;
BA_ "GenMsgTimeoutTime" BO_ 2651930727 2500;
BA_ "GenMsgILSupport" BO_ 2651930727 1;
BA_ "Type" BO_ 2651930734 11;
BA_ "GenMsgTimeoutTime" BO_ 2651930734 2500;
BA_ "GenMsgILSupport" BO_ 2651930734 1;
BA_ "Type" BO_ 2651930672 11;
BA_ "GenMsgTimeoutTime" BO_ 2651930672 2500;
BA_ "GenMsgILSupport" BO_ 2651930672 1;
BA_ "Type" BO_ 2651930675 11;
BA_ "GenMsgTimeoutTime" BO_ 2651930675 2500;
BA_ "GenMsgILSupport" BO_ 2651930675 1;
BA_ "Type" BO_ 2651930676 11;
BA_ "GenMsgTimeoutTime" BO_ 2651930676 2500;
BA_ "GenMsgILSupport" BO_ 2651930676 1;
BA_ "Type" BO_ 2651930659 11;
BA_ "GenMsgTimeoutTime" BO_ 2651930659 2500;
BA_ "GenMsgILSupport" BO_ 2651930659 1;
BA_ "Type" BO_ 2651930660 11;
BA_ "GenMsgTimeoutTime" BO_ 2651930660 2500;
BA_ "GenMsgILSupport" BO_ 2651930660 1;
BA_ "Type" BO_ 2651930687 11;
BA_ "GenMsgTimeoutTime" BO_ 2651930687 2500;
BA_ "GenMsgILSupport" BO_ 2651930687 1;
BA_ "Type" BO_ 134 8;
BA_ "GenMsgTimeoutTime" BO_ 134 2500;
BA_ "GenMsgNrOfRepetition" BO_ 134 3;
BA_ "GenMsgILSupport" BO_ 134 1;
BA_ "GenMsgCycleTimeFast" BO_ 134 250;
BA_ "GenMsgDelayTime" BO_ 134 20;
BA_ "Period [ms]" BO_ 1894 1000;
BA_ "Type" BO_ 1894 1;
BA_ "GenMsgSendType" BO_ 1894 0;
BA_ "GenMsgTimeoutTime" BO_ 1894 2500;
BA_ "GenMsgILSupport" BO_ 1894 1;
BA_ "GenMsgStartDelayTime" BO_ 1894 950;
BA_ "GenMsgCycleTime" BO_ 1894 1000;
BA_ "Period [ms]" BO_ 1478 1000;
BA_ "Type" BO_ 1478 3;
BA_ "GenMsgSendType" BO_ 1478 0;
BA_ "GenMsgTimeoutTime" BO_ 1478 2500;
BA_ "GenMsgILSupport" BO_ 1478 1;
BA_ "GenMsgStartDelayTime" BO_ 1478 550;
BA_ "GenMsgCycleTime" BO_ 1478 1000;
BA_ "GenMsgDelayTime" BO_ 1478 20;
BA_ "Type" BO_ 2564554481 8;
BA_ "GenMsgTimeoutTime" BO_ 2564554481 2500;
BA_ "DiagState" BO_ 2564554481 1;
BA_ "DiagRequest" BO_ 2564457457 1;
BA_ "Type" BO_ 2564457457 8;
BA_ "DiagRequest" BO_ 2564462833 1;
BA_ "Type" BO_ 2564462833 8;
BA_ "DiagRequest" BO_ 2564459249 1;
BA_ "Type" BO_ 2564459249 8;
BA_ "DiagRequest" BO_ 2564459505 1;
BA_ "Type" BO_ 2564459505 8;
BA_ "DiagRequest" BO_ 2564473585 1;
BA_ "Type" BO_ 2564473585 8;
BA_ "DiagRequest" BO_ 2564449009 1;
BA_ "Type" BO_ 2564449009 8;
BA_ "DiagRequest" BO_ 2564449777 1;
BA_ "Type" BO_ 2564449777 8;
BA_ "DiagRequest" BO_ 2564474609 1;
BA_ "Type" BO_ 2564474609 8;
BA_ "DiagRequest" BO_ 2564458481 1;
BA_ "Type" BO_ 2564458481 8;
BA_ "DiagRequest" BO_ 2564442865 1;
BA_ "Type" BO_ 2564442865 8;
BA_ "Type" BO_ 2564485507 8;
BA_ "DiagResponse" BO_ 2564485507 1;
BA_ "Type" BO_ 2564485528 8;
BA_ "DiagResponse" BO_ 2564485528 1;
BA_ "Type" BO_ 2564485514 8;
BA_ "DiagResponse" BO_ 2564485514 1;
BA_ "Type" BO_ 2564485515 8;
BA_ "DiagResponse" BO_ 2564485515 1;
BA_ "Type" BO_ 2564485570 8;
BA_ "DiagResponse" BO_ 2564485570 1;
BA_ "Type" BO_ 2564485474 8;
BA_ "DiagResponse" BO_ 2564485474 1;
BA_ "Type" BO_ 2564485477 8;
BA_ "DiagResponse" BO_ 2564485477 1;
BA_ "Type" BO_ 2564485574 8;
BA_ "DiagResponse" BO_ 2564485574 1;
BA_ "Type" BO_ 2564485511 8;
BA_ "DiagResponse" BO_ 2564485511 1;
BA_ "Type" BO_ 2564485450 8;
BA_ "DiagResponse" BO_ 2564485450 1;
BA_ "Type" BO_ 140 7;
BA_ "GenMsgTimeoutTime" BO_ 140 2500;
BA_ "GenMsgILSupport" BO_ 140 1;
BA_ "GenMsgDelayTime" BO_ 140 20;
BA_ "Period [ms]" BO_ 856 250;
BA_ "Type" BO_ 856 3;
BA_ "GenMsgSendType" BO_ 856 0;
BA_ "GenMsgTimeoutTime" BO_ 856 2500;
BA_ "GenMsgILSupport" BO_ 856 1;
BA_ "GenMsgStartDelayTime" BO_ 856 125;
BA_ "GenMsgCycleTime" BO_ 856 250;
BA_ "GenMsgDelayTime" BO_ 856 20;
BA_ "Type" BO_ 142 7;
BA_ "GenMsgILSupport" BO_ 142 1;
BA_ "Period [ms]" BO_ 852 250;
BA_ "Type" BO_ 852 3;
BA_ "GenMsgSendType" BO_ 852 0;
BA_ "GenMsgILSupport" BO_ 852 1;
BA_ "GenMsgStartDelayTime" BO_ 852 60;
BA_ "GenMsgCycleTime" BO_ 852 250;
BA_ "GenMsgDelayTime" BO_ 852 20;
BA_ "Period [ms]" BO_ 2147485498 1000;
BA_ "Type" BO_ 2147485498 1;
BA_ "GenMsgSendType" BO_ 2147485498 0;
BA_ "GenMsgTimeoutTime" BO_ 2147485498 2500;
BA_ "GenMsgILSupport" BO_ 2147485498 1;
BA_ "GenMsgCycleTime" BO_ 2147485498 1000;
BA_ "GenMsgDelayTime" BO_ 2147485498 20;
BA_ "Period [ms]" BO_ 2147485500 1000;
BA_ "Type" BO_ 2147485500 1;
BA_ "GenMsgSendType" BO_ 2147485500 0;
BA_ "GenMsgTimeoutTime" BO_ 2147485500 2500;
BA_ "GenMsgILSupport" BO_ 2147485500 1;
BA_ "GenMsgCycleTime" BO_ 2147485500 1000;
BA_ "GenMsgDelayTime" BO_ 2147485500 20;
BA_ "Period [ms]" BO_ 2147485502 1000;
BA_ "Type" BO_ 2147485502 1;
BA_ "GenMsgSendType" BO_ 2147485502 0;
BA_ "GenMsgTimeoutTime" BO_ 2147485502 2500;
BA_ "GenMsgILSupport" BO_ 2147485502 1;
BA_ "GenMsgCycleTime" BO_ 2147485502 1000;
BA_ "GenMsgDelayTime" BO_ 2147485502 20;
BA_ "Period [ms]" BO_ 2147485506 1000;
BA_ "Type" BO_ 2147485506 1;
BA_ "GenMsgSendType" BO_ 2147485506 0;
BA_ "GenMsgTimeoutTime" BO_ 2147485506 2500;
BA_ "GenMsgILSupport" BO_ 2147485506 1;
BA_ "GenMsgCycleTime" BO_ 2147485506 1000;
BA_ "GenMsgDelayTime" BO_ 2147485506 20;
BA_ "Type" BO_ 1270 11;
BA_ "GenMsgILSupport" BO_ 1270 1;
BA_ "Type" BO_ 986 11;
BA_ "GenMsgILSupport" BO_ 986 1;
BA_ "GenMsgDelayTime" BO_ 986 20;
BA_ "Period [ms]" BO_ 1468 1000;
BA_ "Type" BO_ 1468 3;
BA_ "GenMsgSendType" BO_ 1468 0;
BA_ "GenMsgILSupport" BO_ 1468 1;
BA_ "GenMsgStartDelayTime" BO_ 1468 50;
BA_ "GenMsgCycleTime" BO_ 1468 1000;
BA_ "GenMsgDelayTime" BO_ 1468 50;
BA_ "Period [ms]" BO_ 1486 1000;
BA_ "Type" BO_ 1486 3;
BA_ "GenMsgSendType" BO_ 1486 0;
BA_ "GenMsgILSupport" BO_ 1486 1;
BA_ "GenMsgStartDelayTime" BO_ 1486 350;
BA_ "GenMsgCycleTime" BO_ 1486 1000;
BA_ "GenMsgDelayTime" BO_ 1486 50;
BA_ "Period [ms]" BO_ 773 200;
BA_ "Type" BO_ 773 3;
BA_ "GenMsgSendType" BO_ 773 0;
BA_ "GenMsgTimeoutTime" BO_ 773 2500;
BA_ "GenMsgILSupport" BO_ 773 1;
BA_ "GenMsgStartDelayTime" BO_ 773 100;
BA_ "GenMsgCycleTime" BO_ 773 200;
BA_ "GenMsgDelayTime" BO_ 773 20;
BA_ "Type" BO_ 2654208046 11;
BA_ "NmMessage" BO_ 2654208046 1;
BA_ "GenMsgTimeoutTime" BO_ 2654208046 2500;
BA_ "GenMsgDelayTime" BO_ 2654208046 500;
BA_ "Period [ms]" BO_ 2654208000 1000;
BA_ "Type" BO_ 2654208000 3;
BA_ "NmMessage" BO_ 2654208000 1;
BA_ "GenMsgSendType" BO_ 2654208000 0;
BA_ "GenMsgTimeoutTime" BO_ 2654208000 2500;
BA_ "GenMsgCycleTime" BO_ 2654208000 1000;
BA_ "Type" BO_ 2654208010 11;
BA_ "NmMessage" BO_ 2654208010 1;
BA_ "GenMsgTimeoutTime" BO_ 2654208010 2500;
BA_ "GenMsgDelayTime" BO_ 2654208010 500;
BA_ "Type" BO_ 2654208103 11;
BA_ "NmMessage" BO_ 2654208103 1;
BA_ "GenMsgTimeoutTime" BO_ 2654208103 2500;
BA_ "GenMsgDelayTime" BO_ 2654208103 500;
BA_ "Type" BO_ 2654208110 11;
BA_ "NmMessage" BO_ 2654208110 1;
BA_ "GenMsgTimeoutTime" BO_ 2654208110 2500;
BA_ "GenMsgDelayTime" BO_ 2654208110 500;
BA_ "Type" BO_ 2654208048 11;
BA_ "NmMessage" BO_ 2654208048 1;
BA_ "GenMsgTimeoutTime" BO_ 2654208048 2500;
BA_ "GenMsgDelayTime" BO_ 2654208048 500;
BA_ "Type" BO_ 2654208003 11;
BA_ "NmMessage" BO_ 2654208003 1;
BA_ "GenMsgTimeoutTime" BO_ 2654208003 2500;
BA_ "GenMsgDelayTime" BO_ 2654208003 500;
BA_ "Type" BO_ 2654208051 11;
BA_ "NmMessage" BO_ 2654208051 1;
BA_ "GenMsgTimeoutTime" BO_ 2654208051 2500;
BA_ "GenMsgDelayTime" BO_ 2654208051 500;
BA_ "Type" BO_ 2654208052 11;
BA_ "NmMessage" BO_ 2654208052 1;
BA_ "GenMsgTimeoutTime" BO_ 2654208052 2500;
BA_ "GenMsgDelayTime" BO_ 2654208052 500;
BA_ "Type" BO_ 2654208035 11;
BA_ "NmMessage" BO_ 2654208035 1;
BA_ "GenMsgTimeoutTime" BO_ 2654208035 2500;
BA_ "GenMsgDelayTime" BO_ 2654208035 500;
BA_ "Type" BO_ 2654208036 11;
BA_ "NmMessage" BO_ 2654208036 1;
BA_ "GenMsgTimeoutTime" BO_ 2654208036 2500;
BA_ "GenMsgDelayTime" BO_ 2654208036 500;
BA_ "Type" BO_ 2654208063 11;
BA_ "NmMessage" BO_ 2654208063 1;
BA_ "GenMsgTimeoutTime" BO_ 2654208063 2500;
BA_ "GenMsgDelayTime" BO_ 2654208063 500;
BA_ "Type" BO_ 950 11;
BA_ "GenMsgILSupport" BO_ 950 1;
BA_ "Period [ms]" BO_ 775 200;
BA_ "Type" BO_ 775 3;
BA_ "GenMsgSendType" BO_ 775 0;
BA_ "GenMsgTimeoutTime" BO_ 775 2500;
BA_ "GenMsgILSupport" BO_ 775 1;
BA_ "GenMsgStartDelayTime" BO_ 775 100;
BA_ "GenMsgCycleTime" BO_ 775 200;
BA_ "GenMsgDelayTime" BO_ 775 20;
BA_ "Period [ms]" BO_ 1890 1000;
BA_ "Type" BO_ 1890 1;
BA_ "GenMsgSendType" BO_ 1890 0;
BA_ "GenMsgILSupport" BO_ 1890 1;
BA_ "GenMsgStartDelayTime" BO_ 1890 750;
BA_ "GenMsgCycleTime" BO_ 1890 1000;
BA_ "Accuracy" SG_ 1884 IgnitionOnCounter "-";
BA_ "Accuracy" SG_ 1474 AIAAlarmCauseSts "-";
BA_ "Event trans." SG_ 1474 AIAAlarmCauseSts 0;
BA_ "GenSigSendType" SG_ 1474 AIAAlarmCauseSts 3;
BA_ "Accuracy" SG_ 1474 AlarmFailSts "-";
BA_ "Event trans." SG_ 1474 AlarmFailSts 0;
BA_ "GenSigSendType" SG_ 1474 AlarmFailSts 3;
BA_ "Accuracy" SG_ 1474 BonnetAlarmCauseSts "-";
BA_ "Event trans." SG_ 1474 BonnetAlarmCauseSts 0;
BA_ "GenSigSendType" SG_ 1474 BonnetAlarmCauseSts 3;
BA_ "Accuracy" SG_ 1474 DoorsAlarmCauseSts "-";
BA_ "Event trans." SG_ 1474 DoorsAlarmCauseSts 0;
BA_ "GenSigSendType" SG_ 1474 DoorsAlarmCauseSts 3;
BA_ "Accuracy" SG_ 1474 ElectricalAlarmCauseSts "-";
BA_ "Event trans." SG_ 1474 ElectricalAlarmCauseSts 0;
BA_ "GenSigSendType" SG_ 1474 ElectricalAlarmCauseSts 3;
BA_ "Accuracy" SG_ 1474 PanicModeActive "-";
BA_ "Event trans." SG_ 1474 PanicModeActive 0;
BA_ "GenSigSendType" SG_ 1474 PanicModeActive 3;
BA_ "Accuracy" SG_ 1474 TrunkAlarmCauseSts "-";
BA_ "Event trans." SG_ 1474 TrunkAlarmCauseSts 0;
BA_ "GenSigSendType" SG_ 1474 TrunkAlarmCauseSts 3;
BA_ "Accuracy" SG_ 1474 USAlarmCauseSts "-";
BA_ "Event trans." SG_ 1474 USAlarmCauseSts 0;
BA_ "GenSigSendType" SG_ 1474 USAlarmCauseSts 3;
BA_ "Accuracy" SG_ 160 BCMFpsCommand "-";
BA_ "Event trans." SG_ 160 BCMFpsCommand 0;
BA_ "GenSigSendType" SG_ 160 BCMFpsCommand 2;
BA_ "Accuracy" SG_ 160 BCMFpsConfirm "-";
BA_ "Event trans." SG_ 160 BCMFpsConfirm 0;
BA_ "GenSigStartValue" SG_ 160 BCMFpsConfirm 1;
BA_ "GenSigSendType" SG_ 160 BCMFpsConfirm 2;
BA_ "Accuracy" SG_ 160 BCMFpsFailSts "-";
BA_ "Event trans." SG_ 160 BCMFpsFailSts 0;
BA_ "GenSigSendType" SG_ 160 BCMFpsFailSts 2;
BA_ "Accuracy" SG_ 160 WasherLevelSts "-";
BA_ "Event trans." SG_ 160 WasherLevelSts 0;
BA_ "GenSigSendType" SG_ 160 WasherLevelSts 3;
BA_ "Event trans." SG_ 2651930624 Digit_01 0;
BA_ "GenSigSendType" SG_ 2651930624 Digit_01 1;
BA_ "Accuracy" SG_ 2651930670 Digit_01_AMP "-";
BA_ "Event trans." SG_ 2651930670 Digit_01_AMP 0;
BA_ "GenSigSendType" SG_ 2651930670 Digit_01_AMP 1;
BA_ "Accuracy" SG_ 2651930670 Digit_02_AMP "-";
BA_ "Accuracy" SG_ 2651930670 Digit_03_AMP "-";
BA_ "Accuracy" SG_ 2651930670 Digit_04_AMP "-";
BA_ "Accuracy" SG_ 2651930670 Digit_05_AMP "-";
BA_ "Accuracy" SG_ 2651930670 Digit_06_AMP "-";
BA_ "Accuracy" SG_ 2651930670 Digit_07_AMP "-";
BA_ "Accuracy" SG_ 2651930670 Digit_08_AMP "-";
BA_ "Accuracy" SG_ 2651930670 Digit_09_AMP "-";
BA_ "Accuracy" SG_ 2651930670 Digit_10_AMP "-";
BA_ "Accuracy" SG_ 2651930670 Digit_11_AMP "-";
BA_ "Accuracy" SG_ 2651930634 Digit_01_CLM "-";
BA_ "Event trans." SG_ 2651930634 Digit_01_CLM 0;
BA_ "GenSigSendType" SG_ 2651930634 Digit_01_CLM 1;
BA_ "Accuracy" SG_ 2651930634 Digit_02_CLM "-";
BA_ "Accuracy" SG_ 2651930634 Digit_03_CLM "-";
BA_ "Accuracy" SG_ 2651930634 Digit_04_CLM "-";
BA_ "Accuracy" SG_ 2651930634 Digit_05_CLM "-";
BA_ "Accuracy" SG_ 2651930634 Digit_06_CLM "-";
BA_ "Accuracy" SG_ 2651930634 Digit_07_CLM "-";
BA_ "Accuracy" SG_ 2651930634 Digit_08_CLM "-";
BA_ "Accuracy" SG_ 2651930634 Digit_09_CLM "-";
BA_ "Accuracy" SG_ 2651930634 Digit_10_CLM "-";
BA_ "Accuracy" SG_ 2651930634 Digit_11_CLM "-";
BA_ "Accuracy" SG_ 2651930727 Digit_01_EMCM "-";
BA_ "Event trans." SG_ 2651930727 Digit_01_EMCM 0;
BA_ "GenSigSendType" SG_ 2651930727 Digit_01_EMCM 1;
BA_ "Accuracy" SG_ 2651930727 Digit_02_EMCM "-";
BA_ "Accuracy" SG_ 2651930727 Digit_03_EMCM "-";
BA_ "Accuracy" SG_ 2651930727 Digit_04_EMCM "-";
BA_ "Accuracy" SG_ 2651930727 Digit_05_EMCM "-";
BA_ "Accuracy" SG_ 2651930727 Digit_06_EMCM "-";
BA_ "Accuracy" SG_ 2651930727 Digit_07_EMCM "-";
BA_ "Accuracy" SG_ 2651930727 Digit_08_EMCM "-";
BA_ "Accuracy" SG_ 2651930727 Digit_09_EMCM "-";
BA_ "Accuracy" SG_ 2651930727 Digit_10_EMCM "-";
BA_ "Accuracy" SG_ 2651930727 Digit_11_EMCM "-";
BA_ "Accuracy" SG_ 2651930734 Digit_01_ESEM "-";
BA_ "Event trans." SG_ 2651930734 Digit_01_ESEM 0;
BA_ "GenSigSendType" SG_ 2651930734 Digit_01_ESEM 1;
BA_ "Accuracy" SG_ 2651930734 Digit_02_ESEM "-";
BA_ "Accuracy" SG_ 2651930734 Digit_03_ESEM "-";
BA_ "Accuracy" SG_ 2651930734 Digit_04_ESEM "-";
BA_ "Accuracy" SG_ 2651930734 Digit_05_ESEM "-";
BA_ "Accuracy" SG_ 2651930734 Digit_06_ESEM "-";
BA_ "Accuracy" SG_ 2651930734 Digit_07_ESEM "-";
BA_ "Accuracy" SG_ 2651930734 Digit_08_ESEM "-";
BA_ "Accuracy" SG_ 2651930734 Digit_09_ESEM "-";
BA_ "Accuracy" SG_ 2651930734 Digit_10_ESEM "-";
BA_ "Accuracy" SG_ 2651930734 Digit_11_ESEM "-";
BA_ "Accuracy" SG_ 2651930672 Digit_01_HMSM "-";
BA_ "Event trans." SG_ 2651930672 Digit_01_HMSM 0;
BA_ "GenSigSendType" SG_ 2651930672 Digit_01_HMSM 1;
BA_ "Accuracy" SG_ 2651930672 Digit_02_HMSM "-";
BA_ "Accuracy" SG_ 2651930672 Digit_03_HMSM "-";
BA_ "Accuracy" SG_ 2651930672 Digit_04_HMSM "-";
BA_ "Accuracy" SG_ 2651930672 Digit_05_HMSM "-";
BA_ "Accuracy" SG_ 2651930672 Digit_06_HMSM "-";
BA_ "Accuracy" SG_ 2651930672 Digit_07_HMSM "-";
BA_ "Accuracy" SG_ 2651930672 Digit_08_HMSM "-";
BA_ "Accuracy" SG_ 2651930672 Digit_09_HMSM "-";
BA_ "Accuracy" SG_ 2651930672 Digit_10_HMSM "-";
BA_ "Accuracy" SG_ 2651930672 Digit_11_HMSM "-";
BA_ "Accuracy" SG_ 2651930675 Digit_01_LBSS "-";
BA_ "Event trans." SG_ 2651930675 Digit_01_LBSS 0;
BA_ "GenSigSendType" SG_ 2651930675 Digit_01_LBSS 1;
BA_ "Accuracy" SG_ 2651930675 Digit_02_LBSS "-";
BA_ "Accuracy" SG_ 2651930675 Digit_03_LBSS "-";
BA_ "Accuracy" SG_ 2651930675 Digit_04_LBSS "-";
BA_ "Accuracy" SG_ 2651930675 Digit_05_LBSS "-";
BA_ "Accuracy" SG_ 2651930675 Digit_06_LBSS "-";
BA_ "Accuracy" SG_ 2651930675 Digit_07_LBSS "-";
BA_ "Accuracy" SG_ 2651930675 Digit_08_LBSS "-";
BA_ "Accuracy" SG_ 2651930675 Digit_09_LBSS "-";
BA_ "Accuracy" SG_ 2651930675 Digit_10_LBSS "-";
BA_ "Accuracy" SG_ 2651930675 Digit_11_LBSS "-";
BA_ "Accuracy" SG_ 2651930676 Digit_01_RBSS "-";
BA_ "Event trans." SG_ 2651930676 Digit_01_RBSS 0;
BA_ "GenSigSendType" SG_ 2651930676 Digit_01_RBSS 1;
BA_ "Accuracy" SG_ 2651930676 Digit_02_RBSS "-";
BA_ "Accuracy" SG_ 2651930676 Digit_03_RBSS "-";
BA_ "Accuracy" SG_ 2651930676 Digit_04_RBSS "-";
BA_ "Accuracy" SG_ 2651930676 Digit_05_RBSS "-";
BA_ "Accuracy" SG_ 2651930676 Digit_06_RBSS "-";
BA_ "Accuracy" SG_ 2651930676 Digit_07_RBSS "-";
BA_ "Accuracy" SG_ 2651930676 Digit_08_RBSS "-";
BA_ "Accuracy" SG_ 2651930676 Digit_09_RBSS "-";
BA_ "Accuracy" SG_ 2651930676 Digit_10_RBSS "-";
BA_ "Accuracy" SG_ 2651930676 Digit_11_RBSS "-";
BA_ "Accuracy" SG_ 2651930659 Digit_01_TBM "-";
BA_ "Event trans." SG_ 2651930659 Digit_01_TBM 0;
BA_ "GenSigSendType" SG_ 2651930659 Digit_01_TBM 1;
BA_ "Accuracy" SG_ 2651930659 Digit_02_TBM "-";
BA_ "Accuracy" SG_ 2651930659 Digit_03_TBM "-";
BA_ "Accuracy" SG_ 2651930659 Digit_04_TBM "-";
BA_ "Accuracy" SG_ 2651930659 Digit_05_TBM "-";
BA_ "Accuracy" SG_ 2651930659 Digit_06_TBM "-";
BA_ "Accuracy" SG_ 2651930659 Digit_07_TBM "-";
BA_ "Accuracy" SG_ 2651930659 Digit_08_TBM "-";
BA_ "Accuracy" SG_ 2651930659 Digit_09_TBM "-";
BA_ "Accuracy" SG_ 2651930659 Digit_10_TBM "-";
BA_ "Accuracy" SG_ 2651930659 Digit_11_TBM "-";
BA_ "Accuracy" SG_ 2651930660 Digit_01_TLM "-";
BA_ "Event trans." SG_ 2651930660 Digit_01_TLM 0;
BA_ "GenSigSendType" SG_ 2651930660 Digit_01_TLM 1;
BA_ "Accuracy" SG_ 2651930660 Digit_02_TLM "-";
BA_ "Accuracy" SG_ 2651930660 Digit_03_TLM "-";
BA_ "Accuracy" SG_ 2651930660 Digit_04_TLM "-";
BA_ "Accuracy" SG_ 2651930660 Digit_05_TLM "-";
BA_ "Accuracy" SG_ 2651930660 Digit_06_TLM "-";
BA_ "Accuracy" SG_ 2651930660 Digit_07_TLM "-";
BA_ "Accuracy" SG_ 2651930660 Digit_08_TLM "-";
BA_ "Accuracy" SG_ 2651930660 Digit_09_TLM "-";
BA_ "Accuracy" SG_ 2651930660 Digit_10_TLM "-";
BA_ "Accuracy" SG_ 2651930660 Digit_11_TLM "-";
BA_ "Accuracy" SG_ 2651930687 Digit_01_TTM "-";
BA_ "Event trans." SG_ 2651930687 Digit_01_TTM 0;
BA_ "GenSigSendType" SG_ 2651930687 Digit_01_TTM 1;
BA_ "Accuracy" SG_ 2651930687 Digit_02_TTM "-";
BA_ "Accuracy" SG_ 2651930687 Digit_03_TTM "-";
BA_ "Accuracy" SG_ 2651930687 Digit_04_TTM "-";
BA_ "Accuracy" SG_ 2651930687 Digit_05_TTM "-";
BA_ "Accuracy" SG_ 2651930687 Digit_06_TTM "-";
BA_ "Accuracy" SG_ 2651930687 Digit_07_TTM "-";
BA_ "Accuracy" SG_ 2651930687 Digit_08_TTM "-";
BA_ "Accuracy" SG_ 2651930687 Digit_09_TTM "-";
BA_ "Accuracy" SG_ 2651930687 Digit_10_TTM "-";
BA_ "Accuracy" SG_ 2651930687 Digit_11_TTM "-";
BA_ "Accuracy" SG_ 134 FPS_Status_Request "-";
BA_ "Event trans." SG_ 134 FPS_Status_Request 0;
BA_ "GenSigSendType" SG_ 134 FPS_Status_Request 2;
BA_ "GenSigStartValue" SG_ 1894 CMP_DIR 15;
BA_ "Event trans." SG_ 1478 AUD_LVLSts 0;
BA_ "GenSigSendType" SG_ 1478 AUD_LVLSts 3;
BA_ "Event trans." SG_ 1478 Autovelox_Gong_Sts 0;
BA_ "GenSigSendType" SG_ 1478 Autovelox_Gong_Sts 3;
BA_ "Event trans." SG_ 1478 BAL_LVLSts 0;
BA_ "GenSigStartValue" SG_ 1478 BAL_LVLSts 10;
BA_ "GenSigSendType" SG_ 1478 BAL_LVLSts 3;
BA_ "Event trans." SG_ 1478 BASS_LVLSts 0;
BA_ "GenSigStartValue" SG_ 1478 BASS_LVLSts 10;
BA_ "GenSigSendType" SG_ 1478 BASS_LVLSts 3;
BA_ "Event trans." SG_ 1478 DSS_ONSts 0;
BA_ "GenSigSendType" SG_ 1478 DSS_ONSts 3;
BA_ "Event trans." SG_ 1478 FD_LVLSts 0;
BA_ "GenSigStartValue" SG_ 1478 FD_LVLSts 10;
BA_ "GenSigSendType" SG_ 1478 FD_LVLSts 3;
BA_ "Event trans." SG_ 1478 INFO1_AUD_ACT 0;
BA_ "GenSigSendType" SG_ 1478 INFO1_AUD_ACT 3;
BA_ "Event trans." SG_ 1478 INFO1_AUD_LEVEL 0;
BA_ "GenSigSendType" SG_ 1478 INFO1_AUD_LEVEL 3;
BA_ "Event trans." SG_ 1478 INFO1_AUD_TYPE 0;
BA_ "GenSigSendType" SG_ 1478 INFO1_AUD_TYPE 3;
BA_ "Event trans." SG_ 1478 INFO2_AUD_ACT 0;
BA_ "GenSigSendType" SG_ 1478 INFO2_AUD_ACT 3;
BA_ "Event trans." SG_ 1478 INFO2_AUD_LEVEL 0;
BA_ "GenSigSendType" SG_ 1478 INFO2_AUD_LEVEL 3;
BA_ "Event trans." SG_ 1478 INFO2_AUD_TYPE 0;
BA_ "GenSigSendType" SG_ 1478 INFO2_AUD_TYPE 3;
BA_ "Event trans." SG_ 1478 MID_LVLSts 0;
BA_ "GenSigStartValue" SG_ 1478 MID_LVLSts 10;
BA_ "GenSigSendType" SG_ 1478 MID_LVLSts 3;
BA_ "Event trans." SG_ 1478 SCV_LVLSts 0;
BA_ "GenSigSendType" SG_ 1478 SCV_LVLSts 3;
BA_ "Event trans." SG_ 1478 TREB_LVLSts 0;
BA_ "GenSigStartValue" SG_ 1478 TREB_LVLSts 10;
BA_ "GenSigSendType" SG_ 1478 TREB_LVLSts 3;
BA_ "Accuracy" SG_ 2564474609 N_PDU "-";
BA_ "Accuracy" SG_ 2564485507 N_PDU "-";
BA_ "Accuracy" SG_ 2564485514 N_PDU "-";
BA_ "Accuracy" SG_ 2564485570 N_PDU "-";
BA_ "Accuracy" SG_ 2564485474 N_PDU "-";
BA_ "Accuracy" SG_ 2564485477 N_PDU "-";
BA_ "Accuracy" SG_ 2564485574 N_PDU "-";
BA_ "Accuracy" SG_ 2564485450 N_PDU "-";
BA_ "Accuracy" SG_ 140 Text_Available "-";
BA_ "Event trans." SG_ 140 Text_Available 0;
BA_ "GenSigSendType" SG_ 140 Text_Available 3;
BA_ "Accuracy" SG_ 140 TP_Enable_Click "-";
BA_ "Event trans." SG_ 140 TP_Enable_Click 0;
BA_ "GenSigStartValue" SG_ 140 TP_Enable_Click 1;
BA_ "GenSigSendType" SG_ 140 TP_Enable_Click 3;
BA_ "Accuracy" SG_ 140 TP_Enable_DoubleClick "-";
BA_ "Event trans." SG_ 140 TP_Enable_DoubleClick 0;
BA_ "GenSigStartValue" SG_ 140 TP_Enable_DoubleClick 1;
BA_ "GenSigSendType" SG_ 140 TP_Enable_DoubleClick 3;
BA_ "Accuracy" SG_ 140 TP_Enable_Longpress "-";
BA_ "Event trans." SG_ 140 TP_Enable_Longpress 0;
BA_ "GenSigStartValue" SG_ 140 TP_Enable_Longpress 1;
BA_ "GenSigSendType" SG_ 140 TP_Enable_Longpress 3;
BA_ "Accuracy" SG_ 140 TP_Enable_Pan "-";
BA_ "Event trans." SG_ 140 TP_Enable_Pan 0;
BA_ "GenSigStartValue" SG_ 140 TP_Enable_Pan 1;
BA_ "GenSigSendType" SG_ 140 TP_Enable_Pan 3;
BA_ "Accuracy" SG_ 140 TP_Enable_Rotate "-";
BA_ "Event trans." SG_ 140 TP_Enable_Rotate 0;
BA_ "GenSigStartValue" SG_ 140 TP_Enable_Rotate 1;
BA_ "GenSigSendType" SG_ 140 TP_Enable_Rotate 3;
BA_ "Accuracy" SG_ 140 TP_Enable_Scroll "-";
BA_ "Event trans." SG_ 140 TP_Enable_Scroll 0;
BA_ "GenSigStartValue" SG_ 140 TP_Enable_Scroll 1;
BA_ "GenSigSendType" SG_ 140 TP_Enable_Scroll 3;
BA_ "Accuracy" SG_ 140 TP_Enable_Swipe "-";
BA_ "Event trans." SG_ 140 TP_Enable_Swipe 0;
BA_ "GenSigStartValue" SG_ 140 TP_Enable_Swipe 1;
BA_ "GenSigSendType" SG_ 140 TP_Enable_Swipe 3;
BA_ "Accuracy" SG_ 140 TP_Enable_Zoom "-";
BA_ "Event trans." SG_ 140 TP_Enable_Zoom 0;
BA_ "GenSigStartValue" SG_ 140 TP_Enable_Zoom 1;
BA_ "GenSigSendType" SG_ 140 TP_Enable_Zoom 3;
BA_ "Accuracy" SG_ 856 Home_Button "-";
BA_ "Event trans." SG_ 856 Home_Button 0;
BA_ "GenSigSendType" SG_ 856 Home_Button 3;
BA_ "Accuracy" SG_ 856 Knob_Capacitive_Switch "-";
BA_ "Event trans." SG_ 856 Knob_Capacitive_Switch 0;
BA_ "GenSigStartValue" SG_ 856 Knob_Capacitive_Switch 15;
BA_ "GenSigSendType" SG_ 856 Knob_Capacitive_Switch 3;
BA_ "Accuracy" SG_ 856 Knob_deflection_push "-";
BA_ "Event trans." SG_ 856 Knob_deflection_push 0;
BA_ "GenSigSendType" SG_ 856 Knob_deflection_push 3;
BA_ "Accuracy" SG_ 856 Knob_Encoder_Direction "-";
BA_ "Event trans." SG_ 856 Knob_Encoder_Direction 0;
BA_ "GenSigStartValue" SG_ 856 Knob_Encoder_Direction 255;
BA_ "GenSigSendType" SG_ 856 Knob_Encoder_Direction 3;
BA_ "Accuracy" SG_ 856 Knob_Encoder_Val "-";
BA_ "Event trans." SG_ 856 Knob_Encoder_Val 0;
BA_ "GenSigSendType" SG_ 856 Knob_Encoder_Val 3;
BA_ "Accuracy" SG_ 856 Option_Button "-";
BA_ "Event trans." SG_ 856 Option_Button 0;
BA_ "GenSigSendType" SG_ 856 Option_Button 3;
BA_ "Accuracy" SG_ 856 Rotary_Volume_Dir "-";
BA_ "Event trans." SG_ 856 Rotary_Volume_Dir 0;
BA_ "GenSigStartValue" SG_ 856 Rotary_Volume_Dir 127;
BA_ "GenSigSendType" SG_ 856 Rotary_Volume_Dir 3;
BA_ "Accuracy" SG_ 856 Rotary_Volume_Val "-";
BA_ "Event trans." SG_ 856 Rotary_Volume_Val 0;
BA_ "GenSigSendType" SG_ 856 Rotary_Volume_Val 3;
BA_ "Accuracy" SG_ 856 SeekMinus "-";
BA_ "Event trans." SG_ 856 SeekMinus 0;
BA_ "GenSigSendType" SG_ 856 SeekMinus 3;
BA_ "Accuracy" SG_ 856 SeekPlus "-";
BA_ "Event trans." SG_ 856 SeekPlus 0;
BA_ "GenSigSendType" SG_ 856 SeekPlus 3;
BA_ "Accuracy" SG_ 142 Text_Available "-";
BA_ "Event trans." SG_ 142 Text_Available 0;
BA_ "GenSigSendType" SG_ 142 Text_Available 3;
BA_ "Accuracy" SG_ 142 TP_Enable_Click "-";
BA_ "Event trans." SG_ 142 TP_Enable_Click 0;
BA_ "GenSigStartValue" SG_ 142 TP_Enable_Click 1;
BA_ "GenSigSendType" SG_ 142 TP_Enable_Click 3;
BA_ "Accuracy" SG_ 142 TP_Enable_DoubleClick "-";
BA_ "Event trans." SG_ 142 TP_Enable_DoubleClick 0;
BA_ "GenSigStartValue" SG_ 142 TP_Enable_DoubleClick 1;
BA_ "GenSigSendType" SG_ 142 TP_Enable_DoubleClick 3;
BA_ "Accuracy" SG_ 142 TP_Enable_Longpress "-";
BA_ "Event trans." SG_ 142 TP_Enable_Longpress 0;
BA_ "GenSigStartValue" SG_ 142 TP_Enable_Longpress 1;
BA_ "GenSigSendType" SG_ 142 TP_Enable_Longpress 3;
BA_ "Accuracy" SG_ 142 TP_Enable_Pan "-";
BA_ "Event trans." SG_ 142 TP_Enable_Pan 0;
BA_ "GenSigStartValue" SG_ 142 TP_Enable_Pan 1;
BA_ "GenSigSendType" SG_ 142 TP_Enable_Pan 3;
BA_ "Accuracy" SG_ 142 TP_Enable_Rotate "-";
BA_ "Event trans." SG_ 142 TP_Enable_Rotate 0;
BA_ "GenSigStartValue" SG_ 142 TP_Enable_Rotate 1;
BA_ "GenSigSendType" SG_ 142 TP_Enable_Rotate 3;
BA_ "Accuracy" SG_ 142 TP_Enable_Scroll "-";
BA_ "Event trans." SG_ 142 TP_Enable_Scroll 0;
BA_ "GenSigStartValue" SG_ 142 TP_Enable_Scroll 1;
BA_ "GenSigSendType" SG_ 142 TP_Enable_Scroll 3;
BA_ "Accuracy" SG_ 142 TP_Enable_Swipe "-";
BA_ "Event trans." SG_ 142 TP_Enable_Swipe 0;
BA_ "GenSigStartValue" SG_ 142 TP_Enable_Swipe 1;
BA_ "GenSigSendType" SG_ 142 TP_Enable_Swipe 3;
BA_ "Accuracy" SG_ 142 TP_Enable_Zoom "-";
BA_ "Event trans." SG_ 142 TP_Enable_Zoom 0;
BA_ "GenSigStartValue" SG_ 142 TP_Enable_Zoom 1;
BA_ "GenSigSendType" SG_ 142 TP_Enable_Zoom 3;
BA_ "Accuracy" SG_ 852 AHBFeature "-";
BA_ "Event trans." SG_ 852 AHBFeature 0;
BA_ "GenSigSendType" SG_ 852 AHBFeature 3;
BA_ "Accuracy" SG_ 852 ALBFeature "-";
BA_ "Accuracy" SG_ 852 DRLFault "-";
BA_ "Accuracy" SG_ 852 FHeatedWindowSts "-";
BA_ "Event trans." SG_ 852 FHeatedWindowSts 0;
BA_ "GenSigSendType" SG_ 852 FHeatedWindowSts 3;
BA_ "Accuracy" SG_ 852 FrontFogLightSts "-";
BA_ "Event trans." SG_ 852 FrontFogLightSts 0;
BA_ "GenSigSendType" SG_ 852 FrontFogLightSts 3;
BA_ "Accuracy" SG_ 852 HeatedMirrorSts "-";
BA_ "Event trans." SG_ 852 HeatedMirrorSts 0;
BA_ "GenSigSendType" SG_ 852 HeatedMirrorSts 3;
BA_ "Accuracy" SG_ 852 HighBeamSts "-";
BA_ "Event trans." SG_ 852 HighBeamSts 0;
BA_ "GenSigSendType" SG_ 852 HighBeamSts 3;
BA_ "Accuracy" SG_ 852 L_TurnLightActivationSts "-";
BA_ "Event trans." SG_ 852 L_TurnLightActivationSts 0;
BA_ "GenSigSendType" SG_ 852 L_TurnLightActivationSts 3;
BA_ "Accuracy" SG_ 852 LHParkingLightSts "-";
BA_ "Event trans." SG_ 852 LHParkingLightSts 0;
BA_ "GenSigSendType" SG_ 852 LHParkingLightSts 3;
BA_ "Accuracy" SG_ 852 LHTurnLightFault "-";
BA_ "Accuracy" SG_ 852 LHTurnSignalSts "-";
BA_ "Event trans." SG_ 852 LHTurnSignalSts 0;
BA_ "GenSigSendType" SG_ 852 LHTurnSignalSts 3;
BA_ "Accuracy" SG_ 852 LowBeamSts "-";
BA_ "Event trans." SG_ 852 LowBeamSts 0;
BA_ "GenSigSendType" SG_ 852 LowBeamSts 3;
BA_ "Accuracy" SG_ 852 ParkingLightFault "-";
BA_ "Accuracy" SG_ 852 PlateLightFault "-";
BA_ "Accuracy" SG_ 852 R_TurnLightActivationSts "-";
BA_ "Event trans." SG_ 852 R_TurnLightActivationSts 0;
BA_ "GenSigSendType" SG_ 852 R_TurnLightActivationSts 3;
BA_ "Accuracy" SG_ 852 RearFogLightFault "-";
BA_ "Accuracy" SG_ 852 RearFogLightSts "-";
BA_ "Event trans." SG_ 852 RearFogLightSts 0;
BA_ "GenSigSendType" SG_ 852 RearFogLightSts 3;
BA_ "Accuracy" SG_ 852 ReverseGearLightFault "-";
BA_ "Accuracy" SG_ 852 RHeatedWindowSts "-";
BA_ "Event trans." SG_ 852 RHeatedWindowSts 0;
BA_ "GenSigSendType" SG_ 852 RHeatedWindowSts 3;
BA_ "Accuracy" SG_ 852 RHParkingLightSts "-";
BA_ "Event trans." SG_ 852 RHParkingLightSts 0;
BA_ "GenSigSendType" SG_ 852 RHParkingLightSts 3;
BA_ "Accuracy" SG_ 852 RHTurnLightFault "-";
BA_ "Accuracy" SG_ 852 RHTurnSignalSts "-";
BA_ "Event trans." SG_ 852 RHTurnSignalSts 0;
BA_ "GenSigSendType" SG_ 852 RHTurnSignalSts 3;
BA_ "Accuracy" SG_ 852 StopLightFault "-";
BA_ "Accuracy" SG_ 852 StopLightSts "-";
BA_ "Event trans." SG_ 852 StopLightSts 0;
BA_ "GenSigSendType" SG_ 852 StopLightSts 3;
BA_ "Accuracy" SG_ 2147485498 GPS_POS1_Lat "0,3017485143";
BA_ "Accuracy" SG_ 2147485498 GPS_POS1_Long "0,3017485143";
BA_ "Accuracy" SG_ 2147485500 GPS_POS2_Alt "0,289926";
BA_ "Accuracy" SG_ 2147485500 GPS_POS2_Ellip "0,289926";
BA_ "Accuracy" SG_ 2147485500 GPS_POS2_Head "0.1";
BA_ "Accuracy" SG_ 2147485500 GPS_POS2_Vel "1";
BA_ "Accuracy" SG_ 2147485502 GPS_POS3_Date_Day "1";
BA_ "Accuracy" SG_ 2147485502 GPS_POS3_Date_Hour "1";
BA_ "Accuracy" SG_ 2147485502 GPS_POS3_Date_Minutes "1";
BA_ "Accuracy" SG_ 2147485502 GPS_POS3_Date_Month "1";
BA_ "Accuracy" SG_ 2147485502 GPS_POS3_Date_Seconds "0.01";
BA_ "Accuracy" SG_ 2147485502 GPS_POS3_Date_Year "1";
BA_ "Accuracy" SG_ 2147485506 GPS_POS5_Hdop "0,1";
BA_ "Accuracy" SG_ 2147485506 GPS_POS5_Pdop "0,1";
BA_ "Accuracy" SG_ 2147485506 GPS_POS5_Trck_Sat "1";
BA_ "Accuracy" SG_ 2147485506 GPS_POS5_Vdop "0,1";
BA_ "Accuracy" SG_ 2147485506 GPS_POS5_Vsbl_Sat "1";
BA_ "Accuracy" SG_ 986 DisplayInfoReceptionSts "-";
BA_ "Event trans." SG_ 986 DisplayInfoReceptionSts 0;
BA_ "GenSigSendType" SG_ 986 DisplayInfoReceptionSts 1;
BA_ "Event trans." SG_ 1468 AmbientLightingLevel 0;
BA_ "GenSigStartValue" SG_ 1468 AmbientLightingLevel 4;
BA_ "GenSigSendType" SG_ 1468 AmbientLightingLevel 3;
BA_ "Event trans." SG_ 1468 AudioRepetition 0;
BA_ "GenSigSendType" SG_ 1468 AudioRepetition 3;
BA_ "Accuracy" SG_ 1468 AutoHighBeamEnable "-";
BA_ "Event trans." SG_ 1468 AutoHighBeamEnable 0;
BA_ "GenSigStartValue" SG_ 1468 AutoHighBeamEnable 1;
BA_ "GenSigSendType" SG_ 1468 AutoHighBeamEnable 3;
BA_ "Event trans." SG_ 1468 AutomaticResetTripB 0;
BA_ "GenSigSendType" SG_ 1468 AutomaticResetTripB 3;
BA_ "Event trans." SG_ 1468 AutoParkBrake 0;
BA_ "GenSigSendType" SG_ 1468 AutoParkBrake 3;
BA_ "Event trans." SG_ 1468 AutoRelock 0;
BA_ "GenSigSendType" SG_ 1468 AutoRelock 3;
BA_ "Event trans." SG_ 1468 BSDEnable 0;
BA_ "GenSigStartValue" SG_ 1468 BSDEnable 2;
BA_ "GenSigSendType" SG_ 1468 BSDEnable 3;
BA_ "Accuracy" SG_ 1468 ConsumptionUnit "-";
BA_ "Event trans." SG_ 1468 ConsumptionUnit 0;
BA_ "GenSigSendType" SG_ 1468 ConsumptionUnit 3;
BA_ "Accuracy" SG_ 1468 CorneringEnable "-";
BA_ "Event trans." SG_ 1468 CorneringEnable 0;
BA_ "GenSigSendType" SG_ 1468 CorneringEnable 3;
BA_ "Accuracy" SG_ 1468 DistanceUnit "-";
BA_ "Event trans." SG_ 1468 DistanceUnit 0;
BA_ "GenSigSendType" SG_ 1468 DistanceUnit 3;
BA_ "Accuracy" SG_ 1468 DRLEnable "-";
BA_ "Event trans." SG_ 1468 DRLEnable 0;
BA_ "GenSigSendType" SG_ 1468 DRLEnable 3;
BA_ "Accuracy" SG_ 1468 ExternalLightSensorLevel "-";
BA_ "Event trans." SG_ 1468 ExternalLightSensorLevel 0;
BA_ "GenSigStartValue" SG_ 1468 ExternalLightSensorLevel 1;
BA_ "GenSigSendType" SG_ 1468 ExternalLightSensorLevel 3;
BA_ "Accuracy" SG_ 1468 GreetingLightsEnable "-";
BA_ "Event trans." SG_ 1468 GreetingLightsEnable 0;
BA_ "GenSigSendType" SG_ 1468 GreetingLightsEnable 3;
BA_ "Accuracy" SG_ 1468 HourMode "-";
BA_ "Event trans." SG_ 1468 HourMode 0;
BA_ "GenSigSendType" SG_ 1468 HourMode 3;
BA_ "Accuracy" SG_ 1468 LanguageSelection "-";
BA_ "Event trans." SG_ 1468 LanguageSelection 0;
BA_ "GenSigSendType" SG_ 1468 LanguageSelection 3;
BA_ "Event trans." SG_ 1468 NavRepetition 0;
BA_ "GenSigSendType" SG_ 1468 NavRepetition 3;
BA_ "Event trans." SG_ 1468 PamAlertMode 0;
BA_ "GenSigStartValue" SG_ 1468 PamAlertMode 2;
BA_ "GenSigSendType" SG_ 1468 PamAlertMode 3;
BA_ "Event trans." SG_ 1468 PamChimeVolumeFront 0;
BA_ "GenSigStartValue" SG_ 1468 PamChimeVolumeFront 1;
BA_ "GenSigSendType" SG_ 1468 PamChimeVolumeFront 3;
BA_ "Event trans." SG_ 1468 PamChimeVolumeRear 0;
BA_ "GenSigStartValue" SG_ 1468 PamChimeVolumeRear 1;
BA_ "GenSigSendType" SG_ 1468 PamChimeVolumeRear 3;
BA_ "Event trans." SG_ 1468 PassiveEntry 0;
BA_ "GenSigSendType" SG_ 1468 PassiveEntry 3;
BA_ "Event trans." SG_ 1468 PhoneRepetition 0;
BA_ "GenSigSendType" SG_ 1468 PhoneRepetition 3;
BA_ "Event trans." SG_ 1468 RemoteDoorUnlock 0;
BA_ "GenSigStartValue" SG_ 1468 RemoteDoorUnlock 1;
BA_ "GenSigSendType" SG_ 1468 RemoteDoorUnlock 3;
BA_ "Event trans." SG_ 1468 Sdw 0;
BA_ "GenSigStartValue" SG_ 1468 Sdw 2;
BA_ "GenSigSendType" SG_ 1468 Sdw 3;
BA_ "Event trans." SG_ 1468 SdwChimeVolume 0;
BA_ "GenSigStartValue" SG_ 1468 SdwChimeVolume 1;
BA_ "GenSigSendType" SG_ 1468 SdwChimeVolume 3;
BA_ "Event trans." SG_ 1468 SoundHornLock 0;
BA_ "GenSigStartValue" SG_ 1468 SoundHornLock 1;
BA_ "GenSigSendType" SG_ 1468 SoundHornLock 3;
BA_ "Event trans." SG_ 1468 SoundHornRemoteStart 0;
BA_ "GenSigSendType" SG_ 1468 SoundHornRemoteStart 3;
BA_ "Accuracy" SG_ 1468 SpeedLockDoorEnable "-";
BA_ "Event trans." SG_ 1468 SpeedLockDoorEnable 0;
BA_ "GenSigSendType" SG_ 1468 SpeedLockDoorEnable 3;
BA_ "Accuracy" SG_ 1468 TelematicSetupACK "-";
BA_ "Event trans." SG_ 1468 TelematicSetupACK 0;
BA_ "GenSigSendType" SG_ 1468 TelematicSetupACK 3;
BA_ "Accuracy" SG_ 1468 TemperatureUnit "-";
BA_ "Event trans." SG_ 1468 TemperatureUnit 0;
BA_ "GenSigSendType" SG_ 1468 TemperatureUnit 3;
BA_ "Event trans." SG_ 1468 TripBEnable 0;
BA_ "GenSigSendType" SG_ 1468 TripBEnable 3;
BA_ "Accuracy" SG_ 1486 AutoUnlockDoorExit "-";
BA_ "Event trans." SG_ 1486 AutoUnlockDoorExit 0;
BA_ "GenSigStartValue" SG_ 1486 AutoUnlockDoorExit 1;
BA_ "GenSigSendType" SG_ 1486 AutoUnlockDoorExit 3;
BA_ "Accuracy" SG_ 1486 BrakeService "-";
BA_ "Event trans." SG_ 1486 BrakeService 0;
BA_ "GenSigSendType" SG_ 1486 BrakeService 3;
BA_ "Accuracy" SG_ 1486 BuzzerVolume "-";
BA_ "Event trans." SG_ 1486 BuzzerVolume 0;
BA_ "GenSigSendType" SG_ 1486 BuzzerVolume 3;
BA_ "Accuracy" SG_ 1486 CalibrationSetup "-";
BA_ "Event trans." SG_ 1486 CalibrationSetup 0;
BA_ "GenSigSendType" SG_ 1486 CalibrationSetup 3;
BA_ "Accuracy" SG_ 1486 EPB_Maintenance_Fdbk "-";
BA_ "Event trans." SG_ 1486 EPB_Maintenance_Fdbk 0;
BA_ "GenSigSendType" SG_ 1486 EPB_Maintenance_Fdbk 3;
BA_ "Accuracy" SG_ 1486 EPB_MaintenanceMode "-";
BA_ "Event trans." SG_ 1486 EPB_MaintenanceMode 0;
BA_ "GenSigSendType" SG_ 1486 EPB_MaintenanceMode 3;
BA_ "Accuracy" SG_ 1486 FlashLightWLock "-";
BA_ "Event trans." SG_ 1486 FlashLightWLock 0;
BA_ "GenSigStartValue" SG_ 1486 FlashLightWLock 1;
BA_ "GenSigSendType" SG_ 1486 FlashLightWLock 3;
BA_ "Accuracy" SG_ 1486 FrontPassengerAirBag "-";
BA_ "Event trans." SG_ 1486 FrontPassengerAirBag 0;
BA_ "GenSigSendType" SG_ 1486 FrontPassengerAirBag 3;
BA_ "Accuracy" SG_ 1486 FSFCWPlusActivationMode "-";
BA_ "Event trans." SG_ 1486 FSFCWPlusActivationMode 0;
BA_ "GenSigStartValue" SG_ 1486 FSFCWPlusActivationMode 1;
BA_ "GenSigSendType" SG_ 1486 FSFCWPlusActivationMode 3;
BA_ "Accuracy" SG_ 1486 FSFCWPlusSetting "-";
BA_ "Event trans." SG_ 1486 FSFCWPlusSetting 0;
BA_ "GenSigStartValue" SG_ 1486 FSFCWPlusSetting 3;
BA_ "GenSigSendType" SG_ 1486 FSFCWPlusSetting 3;
BA_ "Accuracy" SG_ 1486 HeadlightsOffDelay "-";
BA_ "Event trans." SG_ 1486 HeadlightsOffDelay 0;
BA_ "GenSigSendType" SG_ 1486 HeadlightsOffDelay 3;
BA_ "Accuracy" SG_ 1486 HHDisabling "-";
BA_ "Event trans." SG_ 1486 HHDisabling 0;
BA_ "GenSigSendType" SG_ 1486 HHDisabling 3;
BA_ "Accuracy" SG_ 1486 LDW_Sensibility "-";
BA_ "Event trans." SG_ 1486 LDW_Sensibility 0;
BA_ "GenSigStartValue" SG_ 1486 LDW_Sensibility 2;
BA_ "GenSigSendType" SG_ 1486 LDW_Sensibility 3;
BA_ "Accuracy" SG_ 1486 SeltBeltReminder "-";
BA_ "Event trans." SG_ 1486 SeltBeltReminder 0;
BA_ "GenSigSendType" SG_ 1486 SeltBeltReminder 3;
BA_ "Accuracy" SG_ 1486 SpeedLimitSet "-";
BA_ "Event trans." SG_ 1486 SpeedLimitSet 0;
BA_ "GenSigSendType" SG_ 1486 SpeedLimitSet 3;
BA_ "Accuracy" SG_ 1486 SpeedLimitSts "-";
BA_ "Event trans." SG_ 1486 SpeedLimitSts 0;
BA_ "GenSigSendType" SG_ 1486 SpeedLimitSts 3;
BA_ "Accuracy" SG_ 1486 TyrePressureUnit "-";
BA_ "Event trans." SG_ 1486 TyrePressureUnit 0;
BA_ "GenSigStartValue" SG_ 1486 TyrePressureUnit 2;
BA_ "GenSigSendType" SG_ 1486 TyrePressureUnit 3;
BA_ "Accuracy" SG_ 1486 Units "-";
BA_ "Event trans." SG_ 1486 Units 0;
BA_ "GenSigStartValue" SG_ 1486 Units 2;
BA_ "GenSigSendType" SG_ 1486 Units 3;
BA_ "Accuracy" SG_ 1486 VarianceSet "-";
BA_ "Event trans." SG_ 1486 VarianceSet 0;
BA_ "GenSigSendType" SG_ 1486 VarianceSet 3;
BA_ "Event trans." SG_ 773 LbssSysBlockIndSts 0;
BA_ "GenSigSendType" SG_ 773 LbssSysBlockIndSts 3;
BA_ "Event trans." SG_ 773 LbssSysInterfIndSts 0;
BA_ "GenSigSendType" SG_ 773 LbssSysInterfIndSts 3;
BA_ "Event trans." SG_ 773 LbssSysSrvIndSts 0;
BA_ "GenSigSendType" SG_ 773 LbssSysSrvIndSts 3;
BA_ "Event trans." SG_ 773 LbssTmpUnavIndSts 0;
BA_ "GenSigSendType" SG_ 773 LbssTmpUnavIndSts 3;
BA_ "Accuracy" SG_ 2654208046 ActiveLoadSlave_AMP "-";
BA_ "Accuracy" SG_ 2654208046 CurrentFailSts_AMP "-";
BA_ "Accuracy" SG_ 2654208046 D_ES_AMP "-";
BA_ "Accuracy" SG_ 2654208046 EOL_AMP "-";
BA_ "Accuracy" SG_ 2654208046 GenericFailSts_AMP "-";
BA_ "Accuracy" SG_ 2654208046 SystemStatus_AMP "-";
BA_ "Accuracy" SG_ 2654208046 Zero_byte_AMP "-";
BA_ "Accuracy" SG_ 2654208000 ActiveLoadMaster "-";
BA_ "Accuracy" SG_ 2654208000 D_ES_BCM "-";
BA_ "Accuracy" SG_ 2654208000 EOL_BCM "-";
BA_ "Accuracy" SG_ 2654208000 GenericFailSts_BCM "-";
BA_ "Accuracy" SG_ 2654208000 Node0 "-";
BA_ "Accuracy" SG_ 2654208000 Node1 "-";
BA_ "Accuracy" SG_ 2654208000 Node10 "-";
BA_ "Accuracy" SG_ 2654208000 Node11 "-";
BA_ "Accuracy" SG_ 2654208000 Node12 "-";
BA_ "Accuracy" SG_ 2654208000 Node13 "-";
BA_ "Accuracy" SG_ 2654208000 Node14 "-";
BA_ "Accuracy" SG_ 2654208000 Node15 "-";
BA_ "Accuracy" SG_ 2654208000 Node16 "-";
BA_ "Accuracy" SG_ 2654208000 Node17 "-";
BA_ "Accuracy" SG_ 2654208000 Node18 "-";
BA_ "Accuracy" SG_ 2654208000 Node19 "-";
BA_ "Accuracy" SG_ 2654208000 Node2 "-";
BA_ "Accuracy" SG_ 2654208000 Node20 "-";
BA_ "Accuracy" SG_ 2654208000 Node21 "-";
BA_ "Accuracy" SG_ 2654208000 Node22 "-";
BA_ "Accuracy" SG_ 2654208000 Node23 "-";
BA_ "Accuracy" SG_ 2654208000 Node24 "-";
BA_ "Accuracy" SG_ 2654208000 Node25 "-";
BA_ "Accuracy" SG_ 2654208000 Node26 "-";
BA_ "Accuracy" SG_ 2654208000 Node27 "-";
BA_ "Accuracy" SG_ 2654208000 Node28 "-";
BA_ "Accuracy" SG_ 2654208000 Node29 "-";
BA_ "Accuracy" SG_ 2654208000 Node3 "-";
BA_ "Accuracy" SG_ 2654208000 Node30 "-";
BA_ "Accuracy" SG_ 2654208000 Node31 "-";
BA_ "Accuracy" SG_ 2654208000 Node4 "-";
BA_ "Accuracy" SG_ 2654208000 Node5 "-";
BA_ "Accuracy" SG_ 2654208000 Node6 "-";
BA_ "Accuracy" SG_ 2654208000 Node7 "-";
BA_ "Accuracy" SG_ 2654208000 Node8 "-";
BA_ "Accuracy" SG_ 2654208000 Node9 "-";
BA_ "Accuracy" SG_ 2654208000 P_ES "-";
BA_ "Accuracy" SG_ 2654208000 SystemCommand "-";
BA_ "Accuracy" SG_ 2654208000 Zero_byte_BCM "-";
BA_ "Accuracy" SG_ 2654208010 ActiveLoadSlave_Climate "-";
BA_ "Accuracy" SG_ 2654208010 CurrentFailSts_Climate "-";
BA_ "Accuracy" SG_ 2654208010 D_ES_Climate "-";
BA_ "Accuracy" SG_ 2654208010 EOL_Climate "-";
BA_ "Accuracy" SG_ 2654208010 GenericFailSts_Climate "-";
BA_ "Accuracy" SG_ 2654208010 SystemStatus_Climate "-";
BA_ "Accuracy" SG_ 2654208010 Zero_byte_Climate "-";
BA_ "Accuracy" SG_ 2654208103 ActiveLoadSlave_EMCM "-";
BA_ "Accuracy" SG_ 2654208103 CurrentFailSts_EMCM "-";
BA_ "Accuracy" SG_ 2654208103 D_ES_EMCM "-";
BA_ "Accuracy" SG_ 2654208103 EOL_EMCM "-";
BA_ "Accuracy" SG_ 2654208103 GenericFailSts_EMCM "-";
BA_ "Accuracy" SG_ 2654208103 SystemStatus_EMCM "-";
BA_ "Accuracy" SG_ 2654208103 Zero_byte_EMCM "-";
BA_ "Accuracy" SG_ 2654208110 ActiveLoadSlave_ESEM "-";
BA_ "Accuracy" SG_ 2654208110 CurrentFailSts_ESEM "-";
BA_ "Accuracy" SG_ 2654208110 D_ES_ESEM "-";
BA_ "Accuracy" SG_ 2654208110 EOL_ESEM "-";
BA_ "Accuracy" SG_ 2654208110 GenericFailSts_ESEM "-";
BA_ "Accuracy" SG_ 2654208110 SystemStatus_ESEM "-";
BA_ "Accuracy" SG_ 2654208110 Zero_byte_ESEM "-";
BA_ "Accuracy" SG_ 2654208048 ActiveLoadSlave_HMSM "-";
BA_ "Accuracy" SG_ 2654208048 CurrentFailSts_HMSM "-";
BA_ "Accuracy" SG_ 2654208048 D_ES_HMSM "-";
BA_ "Accuracy" SG_ 2654208048 EOL_HMSM "-";
BA_ "Accuracy" SG_ 2654208048 GenericFailSts_HMSM "-";
BA_ "Accuracy" SG_ 2654208048 SystemStatus_HMSM "-";
BA_ "Accuracy" SG_ 2654208048 Zero_byte_HMSM "-";
BA_ "Accuracy" SG_ 2654208003 ActiveLoadSlave_IPC "-";
BA_ "Accuracy" SG_ 2654208003 CurrentFailSts_IPC "-";
BA_ "Accuracy" SG_ 2654208003 D_ES_IPC "-";
BA_ "Accuracy" SG_ 2654208003 EOL_IPC "-";
BA_ "Accuracy" SG_ 2654208003 GenericFailSts_IPC "-";
BA_ "Accuracy" SG_ 2654208003 SystemStatus_IPC "-";
BA_ "Accuracy" SG_ 2654208003 Zero_byte_IPC "-";
BA_ "Accuracy" SG_ 2654208051 ActiveLoadSlave_LBSS "-";
BA_ "Accuracy" SG_ 2654208051 CurrentFailSts_LBSS "-";
BA_ "Accuracy" SG_ 2654208051 D_ES_LBSS "-";
BA_ "Accuracy" SG_ 2654208051 EOL_LBSS "-";
BA_ "Accuracy" SG_ 2654208051 GenericFailSts_LBSS "-";
BA_ "Accuracy" SG_ 2654208051 SystemStatus_LBSS "-";
BA_ "Accuracy" SG_ 2654208051 Zero_byte_LBSS "-";
BA_ "Accuracy" SG_ 2654208052 ActiveLoadSlave_RBSS "-";
BA_ "Accuracy" SG_ 2654208052 CurrentFailSts_RBSS "-";
BA_ "Accuracy" SG_ 2654208052 D_ES_RBSS "-";
BA_ "Accuracy" SG_ 2654208052 EOL_RBSS "-";
BA_ "Accuracy" SG_ 2654208052 GenericFailSts_RBSS "-";
BA_ "Accuracy" SG_ 2654208052 SystemStatus_RBSS "-";
BA_ "Accuracy" SG_ 2654208052 Zero_byte_RBSS "-";
BA_ "Accuracy" SG_ 2654208035 ActiveLoadSlave_TBM "-";
BA_ "Accuracy" SG_ 2654208035 CurrentFailSts_TBM "-";
BA_ "Accuracy" SG_ 2654208035 D_ES_TBM "-";
BA_ "Accuracy" SG_ 2654208035 EOL_TBM "-";
BA_ "Accuracy" SG_ 2654208035 GenericFailSts_TBM "-";
BA_ "Accuracy" SG_ 2654208035 SystemStatus_TBM "-";
BA_ "Accuracy" SG_ 2654208035 Zero_byte_TBM "-";
BA_ "Accuracy" SG_ 2654208036 ActiveLoadSlave_Telematic "-";
BA_ "Accuracy" SG_ 2654208036 CurrentFailSts_Telematic "-";
BA_ "Accuracy" SG_ 2654208036 D_ES_Telematic "-";
BA_ "Accuracy" SG_ 2654208036 EOL_Telematic "-";
BA_ "Accuracy" SG_ 2654208036 GenericFailSts_Telematic "-";
BA_ "Accuracy" SG_ 2654208036 SystemStatus_Telematic "-";
BA_ "Accuracy" SG_ 2654208036 Zero_byte_Telematic "-";
BA_ "Accuracy" SG_ 2654208063 ActiveLoadSlave_TTM "-";
BA_ "Accuracy" SG_ 2654208063 CurrentFailSts_TTM "-";
BA_ "Accuracy" SG_ 2654208063 D_ES_TTM "-";
BA_ "Accuracy" SG_ 2654208063 EOL_TTM "-";
BA_ "Accuracy" SG_ 2654208063 GenericFailSts_TTM "-";
BA_ "Accuracy" SG_ 2654208063 SystemStatus_TTM "-";
BA_ "Accuracy" SG_ 2654208063 Zero_byte_TTM "-";
BA_ "Event trans." SG_ 775 RbssSysBlockIndSts 0;
BA_ "GenSigSendType" SG_ 775 RbssSysBlockIndSts 3;
BA_ "Event trans." SG_ 775 RbssSysInterfIndSts 0;
BA_ "GenSigSendType" SG_ 775 RbssSysInterfIndSts 3;
BA_ "Event trans." SG_ 775 RbssSysSrvIndSts 0;
BA_ "GenSigSendType" SG_ 775 RbssSysSrvIndSts 3;
BA_ "Event trans." SG_ 775 RbssTmpUnavIndSts 0;
BA_ "GenSigSendType" SG_ 775 RbssTmpUnavIndSts 3;
BA_ "Accuracy" SG_ 1890 DaysToService "-";
BA_ "Accuracy" SG_ 1890 DistanceToService "-";
VAL_ 1474 AIAAlarmCauseSts 0 "Not_Active" 1 "Active";
VAL_ 1474 AlarmFailSts 0 "Fail_Not_Present" 1 "Fail_Present";
VAL_ 1474 BonnetAlarmCauseSts 0 "Not_Active" 1 "Active";
VAL_ 1474 DoorsAlarmCauseSts 0 "Not_Active" 1 "Active";
VAL_ 1474 ElectricalAlarmCauseSts 0 "Not_Active" 1 "Active";
VAL_ 1474 PanicModeActive 0 "Not_Active" 1 "Active";
VAL_ 1474 TrunkAlarmCauseSts 0 "Not_Active" 1 "Active";
VAL_ 1474 USAlarmCauseSts 0 "Not_Active" 1 "Active";
VAL_ 160 BCMFpsCommand 0 "Do_Not_Actuate" 1 "Actuate";
VAL_ 160 BCMFpsConfirm 0 "Actuate" 1 "Do_Not_Actuate";
VAL_ 160 BCMFpsFailSts 0 "Fail_not_Present" 1 "Fail_Present";
VAL_ 160 WasherLevelSts 0 "Normal_Level" 1 "Low_Level";
VAL_ 134 FPS_Status_Request 0 "No_FPS_Request" 1 "FPS_Actual_Status_Request";
VAL_ 1894 CMP_DIR 0 "CMP_N" 1 "CMP_N_E" 2 "CMP_E" 3 "CMP_S_E" 4 "CMP_S" 5 "CMP_S_W" 6 "CMP_W" 7 "CMP_N_W" 15 "SNA";
VAL_ 1894 VAR_VAL 15 "SNA";
VAL_ 1478 Autovelox_Gong_Sts 0 "DISABLED" 1 "FAR TO AUTOVELOX" 2 "NEAR TO AUTOVELOX" 3 "SNA";
VAL_ 1478 DSS_ONSts 0 "Surround_Sound_Off" 1 "Surround_Sound_On";
VAL_ 1478 INFO1_AUD_ACT 0 "Not_Active" 1 "Active";
VAL_ 1478 INFO1_AUD_TYPE 0 "None" 1 "TA" 2 "NAV" 3 "VR_Prompt" 4 "Phone_Audio" 5 "Signal_Chime" 6 "E-Call/U-call/ACR" 15 "SNA";
VAL_ 1478 INFO2_AUD_ACT 0 "Not_Active" 1 "Active";
VAL_ 1478 INFO2_AUD_TYPE 0 "None" 1 "TA" 2 "NAV" 3 "VR_Prompt" 4 "Phone_Audio" 5 "Signal_Chime" 6 "E-Call/U-call/ACR" 15 "SNA";
VAL_ 1478 SCV_LVLSts 0 "Off" 1 "Level_1" 2 "Level_2" 3 "Level_3" 4 "Level_4" 5 "Level_5" 6 "Level_6" 7 "SNA";
VAL_ 140 Text_Available 0 "No_Display" 1 "Characters" 2 "Numbers" 3 "Characters_and_Numbers";
VAL_ 140 TP_Enable_Click 0 "Disable" 1 "Enable";
VAL_ 140 TP_Enable_DoubleClick 0 "Disable" 1 "Enable";
VAL_ 140 TP_Enable_Longpress 0 "Disable" 1 "Enable";
VAL_ 140 TP_Enable_Pan 0 "Disable" 1 "Enable";
VAL_ 140 TP_Enable_Rotate 0 "Disable" 1 "Enable";
VAL_ 140 TP_Enable_Scroll 0 "Disable" 1 "Enable";
VAL_ 140 TP_Enable_Swipe 0 "Disable" 1 "Enable";
VAL_ 140 TP_Enable_Zoom 0 "Disable" 1 "Enable";
VAL_ 856 Home_Button 0 "Released" 1 "Pressed";
VAL_ 856 Knob_Capacitive_Switch 0 "Hand Relased" 1 "Touching Level 1" 2 "Touching Level 2" 3 "Touching Level 3" 4 "Touching Level 4" 5 "Touching Level 5" 6 "Touching Level 6" 7 "Touching Level 7" 8 "Touching Level 8" 9 "Touching Level 9" 10 "Touching Level 10" 11 "Touching Level 11" 12 "Touching Level 12" 13 "Touching Level 13" 14 "Touching Level 14" 15 "Hand Touching";
VAL_ 856 Knob_deflection_push 0 "Released" 1 "Pressed" 2 "Right" 3 "Left" 4 "Up" 5 "Down";
VAL_ 856 Knob_Encoder_Val 0 "Knob_no_change" 1 "Knob_incremental (clockwise)" 2 "Knob_decremental" 3 "N/A";
VAL_ 856 Option_Button 0 "Released" 1 "Pressed";
VAL_ 856 Rotary_Volume_Val 0 "Knob_no_change" 1 "Knob_incremental (clockwise)" 2 "Knob_decremental" 3 "Knob_enter";
VAL_ 856 SeekMinus 0 "Released" 1 "Pressed";
VAL_ 856 SeekPlus 0 "Released" 1 "Pressed";
VAL_ 142 Text_Available 0 "No_Display" 1 "Characters" 2 "Numbers" 3 "Characters_and_Numbers";
VAL_ 142 TP_Enable_Click 0 "Disable" 1 "Enable";
VAL_ 142 TP_Enable_DoubleClick 0 "Disable" 1 "Enable";
VAL_ 142 TP_Enable_Longpress 0 "Disable" 1 "Enable";
VAL_ 142 TP_Enable_Pan 0 "Disable" 1 "Enable";
VAL_ 142 TP_Enable_Rotate 0 "Disable" 1 "Enable";
VAL_ 142 TP_Enable_Scroll 0 "Disable" 1 "Enable";
VAL_ 142 TP_Enable_Swipe 0 "Disable" 1 "Enable";
VAL_ 142 TP_Enable_Zoom 0 "Disable" 1 "Enable";
VAL_ 852 AHBFeature 0 "OFF" 1 "ON";
VAL_ 852 ALBFeature 1 "ON" 0 "OFF";
VAL_ 852 DRLFault 0 "False" 1 "True";
VAL_ 852 FHeatedWindowSts 0 "OFF" 1 "ON";
VAL_ 852 FrontFogLightSts 0 "OFF" 1 "ON";
VAL_ 852 HeatedMirrorSts 0 "OFF" 1 "ON";
VAL_ 852 HighBeamSts 0 "OFF" 1 "ON";
VAL_ 852 L_TurnLightActivationSts 0 "Not_Active" 1 "Active";
VAL_ 852 LHParkingLightSts 0 "OFF" 1 "ON";
VAL_ 852 LHTurnLightFault 0 "False" 1 "True";
VAL_ 852 LHTurnSignalSts 0 "OFF" 1 "ON";
VAL_ 852 LowBeamSts 0 "OFF" 1 "ON";
VAL_ 852 ParkingLightFault 0 "False" 1 "True";
VAL_ 852 PlateLightFault 0 "False" 1 "True";
VAL_ 852 R_TurnLightActivationSts 0 "Not_Active" 1 "Active";
VAL_ 852 RearFogLightFault 0 "False" 1 "True";
VAL_ 852 RearFogLightSts 0 "OFF" 1 "ON";
VAL_ 852 ReverseGearLightFault 0 "False" 1 "True";
VAL_ 852 RHeatedWindowSts 0 "OFF" 1 "ON";
VAL_ 852 RHParkingLightSts 0 "OFF" 1 "ON";
VAL_ 852 RHTurnLightFault 0 "False" 1 "True";
VAL_ 852 RHTurnSignalSts 0 "OFF" 1 "ON";
VAL_ 852 StopLightFault 0 "False" 1 "True";
VAL_ 852 StopLightSts 0 "OFF" 1 "ON";
VAL_ 2147485506 GPS_POS5_Fix 0 "NO_FIX" 1 "FIX_2D  " 2 "FIX_3D" 3 "SNA";
VAL_ 1270 AHBFault 0 "OFF" 1 "ON";
VAL_ 1270 BuzzerReqSts_H1 0 "OFF" 1 "Reverse_Gear_Sound_ON" 2 "Others_case_Sound_ON" 3 "Not_used";
VAL_ 1270 DisplaySts 0 "LaneSense_OFF" 1 "LaneSense_ON_HF_ NotA" 2 "SingleLine_Left " 3 "SingleLine_Right" 4 "ON_HF_NotA_NHTSA_on_Left" 5 "ON_HF_NotA_NHTSA _on_Right" 6 "ON_HF_Armed" 7 "ON_HF_Left_SingleLine_Left" 8 "ON_HF_Left_side" 9 "ON_HF_Right_SingleLine_Right " 10 "ON_HF_Right_side" 11 "ON_HF_Left_ NHTSA_on_Left" 12 "ON_HF_Right_NHTSA_on_Right" 13 "ON" 97 "ON_HF_NotA_NoHands" 98 "SingleLine_Left_marker_NoHands" 99 "SingleLine_Right_marker_NoHands" 100 "ON_HF_NotA_NHTSA_on_Left_NoHand" 101 "ON_HF_NotA_NHTSA_on_Right_NoHand" 102 "ON_HF_Armed_NoHands" 103 "ON_HF_Left_SingleLine_Left_NoHand" 104 "ON_HF_Left_NoHands" 105 "ON_HF_Right_ SingleLine_R_NoHand" 106 "ON_HF_Right_NoHands" 107 "ON_HF_Left_NHTSA_on_Left_NoHand" 108 "ON_HF_Right_NHTSA_on_R_NoHand" 160 "Sensor_Blinded" 161 "LaneSense_Temp _Unavailable " 162 "Blinded_LaneSense_AHBC_ON" 240 "LaneSense_Fault" 255 "SNA";
VAL_ 1270 HALF_CHIME_TYPESts 0 "None" 6 "Half_Chime" 15 "SNA";
VAL_ 1270 HALF_LF_CHIME_RQSts 0 "False" 1 "True";
VAL_ 1270 HALF_RF_CHIME_RQSts 0 "False" 1 "True";
VAL_ 1270 SensorBlinded 0 "OFF" 1 "ON";
VAL_ 986 DisplayInfoReceptionSts 0 "Received" 1 "Not_Received";
VAL_ 1468 AmbientLightingLevel 0 "Level_1" 1 "Level_2" 2 "Level_3" 3 "Level_4" 4 "Level_5" 5 "Level_6" 6 "Level_7" 7 "Level_8" 8 "Level_9" 9 "Level_10" 10 "Level_11" 11 "Level_12" 12 "Level_13" 13 "Level_14" 14 "Level_15" 15 "Level_16";
VAL_ 1468 AudioRepetition 0 "On" 1 "Off";
VAL_ 1468 AutoHighBeamEnable 0 "Not_Enable" 1 "Enable";
VAL_ 1468 AutomaticResetTripB 0 "Never" 1 "Always" 2 "2 hours" 3 "8 hours";
VAL_ 1468 AutoParkBrake 0 "On" 1 "Off";
VAL_ 1468 AutoRelock 0 "Disable" 1 "Enable";
VAL_ 1468 BSDEnable 0 "Not_Enable" 1 "Enable_LED" 2 "Enable_ LED_Chime";
VAL_ 1468 ConsumptionUnit 0 "Km_Per_Litre" 1 "Litres_Per_100Km" 2 "Miles_Per_Gallon_UK" 3 "Miles_Per_Gallon_US" 4 "not_used" 5 "not_used" 6 "not_used" 7 "not_used";
VAL_ 1468 CorneringEnable 0 "True" 1 "False";
VAL_ 1468 DistanceUnit 0 "km" 1 "miles";
VAL_ 1468 DRLEnable 0 "True" 1 "False";
VAL_ 1468 ExternalLightSensorLevel 0 "Level_3" 1 "Level_2" 2 "Level_1" 3 "Level_0";
VAL_ 1468 GreetingLightsEnable 0 "True" 1 "False";
VAL_ 1468 HourMode 0 "0_24_h" 1 "0_12_h";
VAL_ 1468 LanguageSelection 0 "Italian" 1 "Deutsch" 2 "English" 3 "Espanol" 4 "Francais" 5 "Portugues" 6 "Polish" 7 "Dutch" 8 "Brazilian" 9 "Turkish" 10 "Mexican" 11 "English_US" 12 "Canadian" 13 "Russian" 14 "Chinese" 15 "Japanese" 16 "Korean" 17 "Arabic";
VAL_ 1468 NavRepetition 0 "Absent" 1 "Present";
VAL_ 1468 PamAlertMode 0 "Off" 1 "Sound" 2 "Sound_Display";
VAL_ 1468 PamChimeVolumeFront 0 "Low" 1 "Medium" 2 "High";
VAL_ 1468 PamChimeVolumeRear 0 "Low" 1 "Medium" 2 "High";
VAL_ 1468 PassiveEntry 0 "On" 1 "Off";
VAL_ 1468 PhoneRepetition 0 "Absent" 1 "Present";
VAL_ 1468 RemoteDoorUnlock 0 "Driver" 1 "All";
VAL_ 1468 Sdw 0 "Off" 1 "Sound" 2 "Sound_Display";
VAL_ 1468 SdwChimeVolume 0 "Low" 1 "Medium" 2 "High";
VAL_ 1468 SoundHornLock 0 "Off" 1 "1st Press" 2 "2nd Press";
VAL_ 1468 SoundHornRemoteStart 0 "On" 1 "Off";
VAL_ 1468 SpeedLockDoorEnable 0 "Not_Enable" 1 "Enable";
VAL_ 1468 TelematicSetupACK 0 "No_ACK_Required" 1 "ACK_KO" 3 "ACK_OK";
VAL_ 1468 TemperatureUnit 0 "°C" 1 "°F";
VAL_ 1468 TripBEnable 0 "Not_Enable" 1 "Enable";
VAL_ 1486 AutoUnlockDoorExit 0 "Not_Enable" 1 "Enable";
VAL_ 1486 BrakeService 0 "Disable" 1 "Enable";
VAL_ 1486 BuzzerVolume 0 "Low" 1 "Mid" 2 "High" 3 "Not_Used";
VAL_ 1486 CalibrationSetup 0 "Disable" 1 "Enable";
VAL_ 1486 EPB_Maintenance_Fdbk 0 "Initialization" 31 "SNA";
VAL_ 1486 EPB_MaintenanceMode 0 "Off" 1 "On";
VAL_ 1486 FlashLightWLock 0 "Off" 1 "On";
VAL_ 1486 FrontPassengerAirBag 0 "Menu_Not_Available" 1 "Disable" 2 "Enable" 3 "SNA";
VAL_ 1486 FSFCWPlusActivationMode 0 "Near" 1 "Med" 2 "Far";
VAL_ 1486 FSFCWPlusSetting 0 "Off" 1 "Audio" 2 "Brake" 3 "Audio_Brake" 4 "Not_Request";
VAL_ 1486 HeadlightsOffDelay 0 "0sec" 1 "30sec" 2 "60sec" 3 "90ec";
VAL_ 1486 HHDisabling 0 "Disable" 1 "Enable";
VAL_ 1486 LDW_Sensibility 0 "Early" 1 "Med" 2 "Late";
VAL_ 1486 SeltBeltReminder 0 "Disable" 1 "Enable";
VAL_ 1486 SpeedLimitSts 0 "Disable" 1 "Enable";
VAL_ 1486 TyrePressureUnit 0 "KPa" 1 "psi" 2 "bar";
VAL_ 1486 Units 0 "US" 1 "Imperial" 2 "Metric" 3 "Custom";
VAL_ 773 LbssSysBlockIndSts 0 "False" 1 "True";
VAL_ 773 LbssSysInterfIndSts 0 "False" 1 "True";
VAL_ 773 LbssSysSrvIndSts 0 "False" 1 "True";
VAL_ 773 LbssTmpUnavIndSts 0 "False" 1 "True";
VAL_ 2654208046 ActiveLoadSlave_AMP 0 "No_Active_Loads_in_Slave" 1 "Active_Loads_in_Slave";
VAL_ 2654208046 CurrentFailSts_AMP 0 "No_Fail_Present" 1 "Fail_Present";
VAL_ 2654208046 D_ES_AMP 0 "Error_Active_State" 1 "Error_Passive_Warning_State" 2 "Bus_Off_State" 3 "Not_Used";
VAL_ 2654208046 EOL_AMP 0 "No_EOL_Programming" 1 "EOL_Programming";
VAL_ 2654208046 GenericFailSts_AMP 0 "No_Fail_Present" 1 "Fail_Present";
VAL_ 2654208046 SystemStatus_AMP 0 "Wake_up" 1 "Not_Used" 2 "StayActive" 3 "Not_Used";
VAL_ 2654208046 Zero_byte_AMP 0 "Fixed";
VAL_ 2654208000 ActiveLoadMaster 0 "No_Active_loads_in_master" 1 "Active_loads_in_master";
VAL_ 2654208000 D_ES_BCM 0 "Error_Active_State" 1 "Error_Passive_Warning_State" 2 "Bus_Off_State" 3 "Not_Used";
VAL_ 2654208000 EOL_BCM 0 "No_EOL_Programming" 1 "EOL_Programming";
VAL_ 2654208000 GenericFailSts_BCM 0 "No_FunctionalFailPresent" 1 "FunctionalFailPresent";
VAL_ 2654208000 Node0 0 "Not_active" 1 "Active";
VAL_ 2654208000 Node1 0 "Not_active" 1 "Active";
VAL_ 2654208000 Node10 0 "Not_active" 1 "Active";
VAL_ 2654208000 Node11 0 "Not_active" 1 "Active";
VAL_ 2654208000 Node12 0 "Not_active" 1 "Active";
VAL_ 2654208000 Node13 0 "Not_active" 1 "Active";
VAL_ 2654208000 Node14 0 "Not_active" 1 "Active";
VAL_ 2654208000 Node15 0 "Not_active" 1 "Active";
VAL_ 2654208000 Node16 0 "Not_active" 1 "Active";
VAL_ 2654208000 Node17 0 "Not_active" 1 "Active";
VAL_ 2654208000 Node18 0 "Not_active" 1 "Active";
VAL_ 2654208000 Node19 0 "Not_active" 1 "Active";
VAL_ 2654208000 Node2 0 "Not_active" 1 "Active";
VAL_ 2654208000 Node20 0 "Not_active" 1 "Active";
VAL_ 2654208000 Node21 0 "Not_active" 1 "Active";
VAL_ 2654208000 Node22 0 "Not_active" 1 "Active";
VAL_ 2654208000 Node23 0 "Not_active" 1 "Active";
VAL_ 2654208000 Node24 0 "Not_active" 1 "Active";
VAL_ 2654208000 Node25 0 "Not_active" 1 "Active";
VAL_ 2654208000 Node26 0 "Not_active" 1 "Active";
VAL_ 2654208000 Node27 0 "Not_active" 1 "Active";
VAL_ 2654208000 Node28 0 "Not_active" 1 "Active";
VAL_ 2654208000 Node29 0 "Not_active" 1 "Active";
VAL_ 2654208000 Node3 0 "Not_active" 1 "Active";
VAL_ 2654208000 Node30 0 "Not_active" 1 "Active";
VAL_ 2654208000 Node31 0 "Not_active" 1 "Active";
VAL_ 2654208000 Node4 0 "Not_active" 1 "Active";
VAL_ 2654208000 Node5 0 "Not_active" 1 "Active";
VAL_ 2654208000 Node6 0 "Not_active" 1 "Active";
VAL_ 2654208000 Node7 0 "Not_active" 1 "Active";
VAL_ 2654208000 Node8 0 "Not_active" 1 "Active";
VAL_ 2654208000 Node9 0 "Not_active" 1 "Active";
VAL_ 2654208000 P_ES 0 "Fail_Not_Present" 1 "Fail_Present";
VAL_ 2654208000 SystemCommand 0 "Wake_up" 1 "Not_Used" 2 "StayActive" 3 "Sleep";
VAL_ 2654208000 Zero_byte_BCM 0 "Fixed";
VAL_ 2654208010 ActiveLoadSlave_Climate 0 "No_Active_Loads_in_Slave" 1 "Active_Loads_in_Slave";
VAL_ 2654208010 CurrentFailSts_Climate 0 "No_Fail_Present" 1 "Fail_Present";
VAL_ 2654208010 D_ES_Climate 0 "Error_Active_State" 1 "Error_Passive_Warning_State" 2 "Bus_Off_State" 3 "Not_Used";
VAL_ 2654208010 EOL_Climate 0 "No_EOL_Programming" 1 "EOL_Programming";
VAL_ 2654208010 GenericFailSts_Climate 0 "No_Fail_Present" 1 "Fail_Present";
VAL_ 2654208010 SystemStatus_Climate 0 "Wake_up" 1 "Not_Used" 2 "StayActive" 3 "Not_Used";
VAL_ 2654208010 Zero_byte_Climate 0 "Fixed";
VAL_ 2654208103 ActiveLoadSlave_EMCM 0 "No_Active_Loads_in_Slave" 1 "Active_Loads_in_Slave";
VAL_ 2654208103 CurrentFailSts_EMCM 0 "No_Fail_Present" 1 "Fail_Present";
VAL_ 2654208103 D_ES_EMCM 0 "Error_Active_State" 1 "Error_Passive_Warning_State" 2 "Bus_Off_State" 3 "Not_Used";
VAL_ 2654208103 EOL_EMCM 0 "No_EOL_Programming" 1 "EOL_Programming";
VAL_ 2654208103 GenericFailSts_EMCM 0 "No_Fail_Present" 1 "Fail_Present";
VAL_ 2654208103 SystemStatus_EMCM 0 "Wake_up" 1 "Not_Used" 2 "StayActive" 3 "Not_Used";
VAL_ 2654208103 Zero_byte_EMCM 0 "Fixed";
VAL_ 2654208110 ActiveLoadSlave_ESEM 0 "No_Active_Loads_in_Slave" 1 "Active_Loads_in_Slave";
VAL_ 2654208110 CurrentFailSts_ESEM 0 "No_Fail_Present" 1 "Fail_Present";
VAL_ 2654208110 D_ES_ESEM 0 "Error_Active_State" 1 "Error_Passive_Warning_State" 2 "Bus_Off_State" 3 "Not_Used";
VAL_ 2654208110 EOL_ESEM 0 "No_EOL_Programming" 1 "EOL_Programming";
VAL_ 2654208110 GenericFailSts_ESEM 0 "No_Fail_Present" 1 "Fail_Present";
VAL_ 2654208110 SystemStatus_ESEM 0 "Wake_up" 1 "Not_Used" 2 "StayActive" 3 "Not_Used";
VAL_ 2654208110 Zero_byte_ESEM 0 "Fixed";
VAL_ 2654208048 ActiveLoadSlave_HMSM 0 "No_Active_Loads_in_Slave" 1 "Active_Loads_in_Slave";
VAL_ 2654208048 CurrentFailSts_HMSM 0 "No_Fail_Present" 1 "Fail_Present";
VAL_ 2654208048 D_ES_HMSM 0 "Error_Active_State" 1 "Error_Passive_Warning_State" 2 "Bus_Off_State" 3 "Not_Used";
VAL_ 2654208048 EOL_HMSM 0 "No_EOL_Programming" 1 "EOL_Programming";
VAL_ 2654208048 GenericFailSts_HMSM 0 "No_Fail_Present" 1 "Fail_Present";
VAL_ 2654208048 SystemStatus_HMSM 0 "Wake_up" 1 "Not_Used" 2 "StayActive" 3 "Not_Used";
VAL_ 2654208048 Zero_byte_HMSM 0 "Fixed";
VAL_ 2654208003 ActiveLoadSlave_IPC 0 "No_Active_Loads_in_Slave" 1 "Active_Loads_in_Slave";
VAL_ 2654208003 CurrentFailSts_IPC 0 "No_Fail_Present" 1 "Fail_Present";
VAL_ 2654208003 D_ES_IPC 0 "Error_Active_State" 1 "Error_Passive_Warning_State" 2 "Bus_Off_State" 3 "Not_Used";
VAL_ 2654208003 EOL_IPC 0 "No_EOL_Programming" 1 "EOL_Programming";
VAL_ 2654208003 GenericFailSts_IPC 0 "No_Fail_Present" 1 "Fail_Present";
VAL_ 2654208003 SystemStatus_IPC 0 "Wake_up" 1 "Not_Used" 2 "StayActive" 3 "Not_Used";
VAL_ 2654208003 Zero_byte_IPC 0 "Fixed";
VAL_ 2654208051 ActiveLoadSlave_LBSS 0 "No_Active_Loads_in_Slave" 1 "Active_Loads_in_Slave";
VAL_ 2654208051 CurrentFailSts_LBSS 0 "No_Fail_Present" 1 "Fail_Present";
VAL_ 2654208051 D_ES_LBSS 0 "Error_Active_State" 1 "Error_Passive_Warning_State" 2 "Bus_Off_State" 3 "Not_Used";
VAL_ 2654208051 EOL_LBSS 0 "No_EOL_Programming" 1 "EOL_Programming";
VAL_ 2654208051 GenericFailSts_LBSS 0 "No_Fail_Present" 1 "Fail_Present";
VAL_ 2654208051 SystemStatus_LBSS 0 "Wake_up" 1 "Not_Used" 2 "StayActive" 3 "Not_Used";
VAL_ 2654208051 Zero_byte_LBSS 0 "Fixed";
VAL_ 2654208052 ActiveLoadSlave_RBSS 0 "No_Active_Loads_in_Slave" 1 "Active_Loads_in_Slave";
VAL_ 2654208052 CurrentFailSts_RBSS 0 "No_Fail_Present" 1 "Fail_Present";
VAL_ 2654208052 D_ES_RBSS 0 "Error_Active_State" 1 "Error_Passive_Warning_State" 2 "Bus_Off_State" 3 "Not_Used";
VAL_ 2654208052 EOL_RBSS 0 "No_EOL_Programming" 1 "EOL_Programming";
VAL_ 2654208052 GenericFailSts_RBSS 0 "No_Fail_Present" 1 "Fail_Present";
VAL_ 2654208052 SystemStatus_RBSS 0 "Wake_up" 1 "Not_Used" 2 "StayActive" 3 "Not_Used";
VAL_ 2654208052 Zero_byte_RBSS 0 "Fixed";
VAL_ 2654208035 ActiveLoadSlave_TBM 0 "No_Active_Loads_in_Slave" 1 "Active_Loads_in_Slave";
VAL_ 2654208035 CurrentFailSts_TBM 0 "No_Fail_Present" 1 "Fail_Present";
VAL_ 2654208035 D_ES_TBM 0 "Error_Active_State" 1 "Error_Passive_Warning_State" 2 "Bus_Off_State" 3 "Not_Used";
VAL_ 2654208035 EOL_TBM 0 "No_EOL_Programming" 1 "EOL_Programming";
VAL_ 2654208035 GenericFailSts_TBM 0 "No_Fail_Present" 1 "Fail_Present";
VAL_ 2654208035 SystemStatus_TBM 0 "Wake_up" 1 "Not_Used" 2 "StayActive" 3 "Not_Used";
VAL_ 2654208035 Zero_byte_TBM 0 "Fixed";
VAL_ 2654208036 ActiveLoadSlave_Telematic 0 "No_Active_Loads_in_Slave" 1 "Active_Loads_in_Slave";
VAL_ 2654208036 CurrentFailSts_Telematic 0 "No_Fail_Present" 1 "Fail_Present";
VAL_ 2654208036 D_ES_Telematic 0 "Error_Active_State" 1 "Error_Passive_Warning_State" 2 "Bus_Off_State" 3 "Not_Used";
VAL_ 2654208036 EOL_Telematic 0 "No_EOL_Programming" 1 "EOL_Programming";
VAL_ 2654208036 GenericFailSts_Telematic 0 "No_Fail_Present" 1 "Fail_Present";
VAL_ 2654208036 SystemStatus_Telematic 0 "Wake_up" 1 "Not_Used" 2 "StayActive" 3 "Not_Used";
VAL_ 2654208036 Zero_byte_Telematic 0 "Fixed";
VAL_ 2654208063 ActiveLoadSlave_TTM 0 "No_Active_Loads_in_Slave" 1 "Active_Loads_in_Slave";
VAL_ 2654208063 CurrentFailSts_TTM 0 "No_Fail_Present" 1 "Fail_Present";
VAL_ 2654208063 D_ES_TTM 0 "Error_Active_State" 1 "Error_Passive_Warning_State" 2 "Bus_Off_State" 3 "Not_Used";
VAL_ 2654208063 EOL_TTM 0 "No_EOL_Programming" 1 "EOL_Programming";
VAL_ 2654208063 GenericFailSts_TTM 0 "No_Fail_Present" 1 "Fail_Present";
VAL_ 2654208063 SystemStatus_TTM 0 "Wake_up" 1 "Not_Used" 2 "StayActive" 3 "Not_Used";
VAL_ 2654208063 Zero_byte_TTM 0 "Fixed";
VAL_ 950 Alert_CHF 0 "No_object_detected" 1 "1_Arc" 2 "2_Arc" 3 "3_Arc" 4 "4_Arc" 5 "5_Arc" 6 "6_Arc" 7 "SNA";
VAL_ 950 Alert_CHR 0 "No_object_detected" 1 "1_Arc" 2 "2_Arc" 3 "3_Arc" 4 "4_Arc" 5 "5_Arc" 6 "6_Arc" 7 "SNA";
VAL_ 950 Alert_LHF 0 "No_object_detected" 1 "1_Arc" 2 "2_Arc" 7 "SNA";
VAL_ 950 Alert_LHR 0 "No_object_detected" 1 "1_Arc" 2 "2_Arc" 7 "SNA";
VAL_ 950 Alert_RHF 0 "No_object_detected" 1 "1_Arc" 2 "2_Arc" 7 "SNA";
VAL_ 950 Alert_RHR 0 "No_object_detected" 1 "1_Arc" 2 "2_Arc" 7 "SNA";
VAL_ 950 ChimeActivation_LHF 0 "NotActive" 1 "Active";
VAL_ 950 ChimeActivation_LHR 0 "NotActive" 1 "Active";
VAL_ 950 ChimeActivation_RHF 0 "NotActive" 1 "Active";
VAL_ 950 ChimeActivation_RHR 0 "NotActive" 1 "Active";
VAL_ 950 ChimeType_Front 0 "Type4" 1 "Type5";
VAL_ 950 ChimeType_Rear 0 "Type4" 1 "Type5";
VAL_ 950 DisplayActivation 0 "NotActive" 1 "Active";
VAL_ 950 Graphic_CHF 0 "Slow_flash" 1 "Solid" 2 "None" 3 "SNA";
VAL_ 950 Graphic_CHR 0 "Slow_flash" 1 "Solid" 2 "None" 3 "SNA";
VAL_ 950 Graphic_LHF 0 "Slow_flash" 1 "Solid" 2 "None" 3 "SNA";
VAL_ 950 Graphic_LHR 0 "Slow_flash" 1 "Solid" 2 "None" 3 "SNA";
VAL_ 950 Graphic_RHF 0 "Slow_flash" 1 "Solid" 2 "None" 3 "SNA";
VAL_ 950 Graphic_RHR 0 "Slow_flash" 1 "Solid" 2 "None" 3 "SNA";
VAL_ 775 RbssSysBlockIndSts 0 "False" 1 "True";
VAL_ 775 RbssSysInterfIndSts 0 "False" 1 "True";
VAL_ 775 RbssSysSrvIndSts 0 "False" 1 "True";
VAL_ 775 RbssTmpUnavIndSts 0 "False" 1 "True";
VAL_ 1890 DaysToService 511 "SNA";
VAL_ 1890 DistanceToService 131071 "SNA";
